[part 1 of 2: packages /VehicleProject to /Cluster]
AUTOSAR XML (schema 00048)
package /VehicleProject
  system System
package /TP
  can tp config KAMA_FP_EPT_0303_CAN: communication-cluster=KAMA_FP_EPT_0303, can-tp-ecu{cycle-time-main-function=0.005, ecu-instance=VCU}
    can tp channel TPCH: channel-id=1, channel-mode=FULL-DUPLEX-MODE
    can-tp-connection addressing-format=STANDARD, can-tp-channel=TPCH, data-pdu=AllFunctionRequest_Tp_oKAMA_FP_EPT_0303, receiver=TN_VCU, ta-type=FUNCTIONAL, tp-sdu=AllFunctionRequest_oKAMA_FP_EPT_0303, transmitter=TN_Diag:
      ident AllFunctionRequest_oTN_Diag
    can-tp-connection addressing-format=STANDARD, can-tp-channel=TPCH, data-pdu=OBDFunRequest_Tp_oKAMA_FP_EPT_0303, receiver=TN_VCU, ta-type=FUNCTIONAL, tp-sdu=OBDFunRequest_oKAMA_FP_EPT_0303, transmitter=TN_OBDDiag:
      ident OBDFunRequest_oTN_OBDDiag
    can-tp-connection addressing-format=STANDARD, can-tp-channel=TPCH, data-pdu=UDSFunRequest_Tp_oKAMA_FP_EPT_0303, receiver=TN_VCU, ta-type=FUNCTIONAL, tp-sdu=UDSFunRequest_oKAMA_FP_EPT_0303, transmitter=TN_Diag:
      ident UDSFunRequest_oTN_Diag
    can-tp-connection addressing-format=STANDARD, can-tp-channel=TPCH, data-pdu=OBDRequest_Tp_oKAMA_FP_EPT_0303, flow-control-pdu=OBDResponse_Tp_oKAMA_FP_EPT_0303, receiver=TN_VCU, ta-type=PHYSICAL, tp-sdu=OBDRequest_oKAMA_FP_EPT_0303, transmitter=TN_OBDDiag:
      ident OBDRequest_oTN_VCU
    can-tp-connection addressing-format=STANDARD, can-tp-channel=TPCH, data-pdu=OBDResponse_Tp_oKAMA_FP_EPT_0303, flow-control-pdu=OBDRequest_Tp_oKAMA_FP_EPT_0303, receiver=TN_OBDDiag, ta-type=PHYSICAL, tp-sdu=OBDResponse_oKAMA_FP_EPT_0303, transmitter=TN_VCU:
      ident OBDResponse_oTN_VCU
    can-tp-connection addressing-format=STANDARD, can-tp-channel=TPCH, data-pdu=UDSRequest_Tp_oKAMA_FP_EPT_0303, flow-control-pdu=UDSResponse_Tp_oKAMA_FP_EPT_0303, receiver=TN_VCU, ta-type=PHYSICAL, tp-sdu=UDSRequest_oKAMA_FP_EPT_0303, transmitter=TN_Diag:
      ident UDSRequest_oTN_VCU
    can-tp-connection addressing-format=STANDARD, can-tp-channel=TPCH, data-pdu=UDSResponse_Tp_oKAMA_FP_EPT_0303, flow-control-pdu=UDSRequest_Tp_oKAMA_FP_EPT_0303, receiver=TN_Diag, ta-type=PHYSICAL, tp-sdu=UDSResponse_oKAMA_FP_EPT_0303, transmitter=TN_VCU:
      ident UDSResponse_oTN_VCU
    can tp node TN_Diag
    can tp node TN_OBDDiag
    can tp node TN_VCU: connector=CN_KAMA_FP_EPT_0303
package /Cluster
  can cluster KAMA_FP_EPSChassis1_0303: baudrate=500000, protocol-name=CAN
    can physical channel CHNL: comm-connectors=CN_KAMA_FP_EPSChassis1_0303
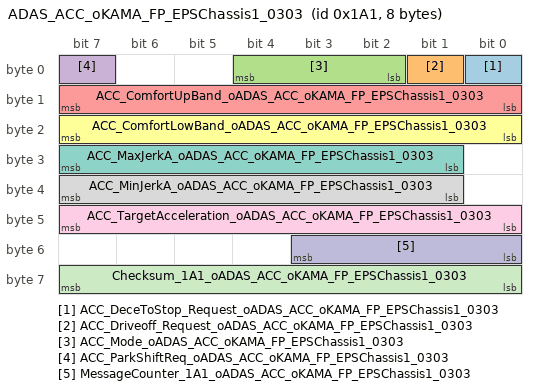
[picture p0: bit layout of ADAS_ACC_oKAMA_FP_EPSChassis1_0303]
      frame ADAS_ACC_oKAMA_FP_EPSChassis1_0303: id 0x1A1, to VCU, frame-length=8, can-addressing-mode=STANDARD
        pdu ADAS_ACC_oKAMA_FP_EPSChassis1_0303: length=8, minimum-delay=0, transmission-mode-false-timing=cyclic-timing={time-offset=0, time-period=0.02}, transmission-mode-true-timing=cyclic-timing={time-offset=0, time-period=0.02}, unused-bit-pattern=0
          signal ACC_DeceToStop_Request_oADAS_ACC_oKAMA_FP_EPSChassis1_0303: start 0, 1 bit, big-endian, i-signal-type=PRIMITIVE, init-value=0, base-type=boolean, compu-method=CM_ACC_DeceToStop_Request, data-constr=DC_ACC_DeceToStop_Request, transfer-property=PENDING, to VCU
          signal ACC_Driveoff_Request_oADAS_ACC_oKAMA_FP_EPSChassis1_0303: start 1, 1 bit, big-endian, i-signal-type=PRIMITIVE, init-value=0, base-type=boolean, compu-method=CM_ACC_Driveoff_Request, data-constr=DC_ACC_Driveoff_Request, transfer-property=PENDING, to VCU
          signal ACC_Mode_oADAS_ACC_oKAMA_FP_EPSChassis1_0303: start 4, 3 bit, big-endian, i-signal-type=PRIMITIVE, init-value=0, base-type=uint8, compu-method=CM_ACC_Mode, data-constr=DC_ACC_Mode, transfer-property=PENDING, to VCU
          signal ACC_ParkShiftReq_oADAS_ACC_oKAMA_FP_EPSChassis1_0303: start 7, 1 bit, big-endian, i-signal-type=PRIMITIVE, init-value=0, base-type=boolean, compu-method=CM_ACC_ParkShiftReq, data-constr=DC_ACC_ParkShiftReq, transfer-property=PENDING, to VCU
          signal ACC_ComfortUpBand_oADAS_ACC_oKAMA_FP_EPSChassis1_0303: start 15, 8 bit, big-endian, i-signal-type=PRIMITIVE, init-value=140, base-type=uint8, compu-method=CM_ACC_ComfortUpBand, data-constr=DC_ACC_ComfortUpBand, transfer-property=PENDING, to VCU
          signal ACC_ComfortLowBand_oADAS_ACC_oKAMA_FP_EPSChassis1_0303: start 23, 8 bit, big-endian, i-signal-type=PRIMITIVE, init-value=140, base-type=uint8, compu-method=CM_ACC_ComfortLowBand, data-constr=DC_ACC_ComfortLowBand, transfer-property=PENDING, to VCU
          signal ACC_MaxJerkA_oADAS_ACC_oKAMA_FP_EPSChassis1_0303: start 31, 7 bit, big-endian, i-signal-type=PRIMITIVE, init-value=0, base-type=uint8, compu-method=CM_ACC_MaxJerkA, data-constr=DC_ACC_MaxJerkA, transfer-property=PENDING, to VCU
          signal ACC_MinJerkA_oADAS_ACC_oKAMA_FP_EPSChassis1_0303: start 39, 7 bit, big-endian, i-signal-type=PRIMITIVE, init-value=127, base-type=uint8, compu-method=CM_ACC_MinJerkA, data-constr=DC_ACC_MinJerkA, transfer-property=PENDING, to VCU
          signal ACC_TargetAcceleration_oADAS_ACC_oKAMA_FP_EPSChassis1_0303: start 47, 8 bit, big-endian, i-signal-type=PRIMITIVE, init-value=140, base-type=uint8, compu-method=CM_ACC_TargetAcceleration, data-constr=DC_ACC_TargetAcceleration, unit=U_mYsX2, transfer-property=PENDING, to VCU
          signal MessageCounter_1A1_oADAS_ACC_oKAMA_FP_EPSChassis1_0303: start 51, 4 bit, big-endian, i-signal-type=PRIMITIVE, init-value=0, base-type=uint8, compu-method=CM_MessageCounter_1A1, data-constr=DC_MessageCounter_1A1, transfer-property=PENDING, to VCU
          signal Checksum_1A1_oADAS_ACC_oKAMA_FP_EPSChassis1_0303: start 63, 8 bit, big-endian, i-signal-type=PRIMITIVE, init-value=0, base-type=uint8, compu-method=CM_Checksum_1A1, data-constr=DC_Checksum_1A1, transfer-property=PENDING, to VCU
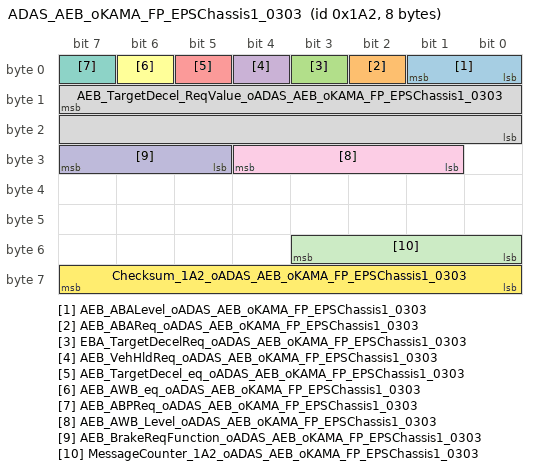
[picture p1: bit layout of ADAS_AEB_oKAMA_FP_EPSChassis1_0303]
      frame ADAS_AEB_oKAMA_FP_EPSChassis1_0303: id 0x1A2, to VCU, frame-length=8, can-addressing-mode=STANDARD
        pdu ADAS_AEB_oKAMA_FP_EPSChassis1_0303: length=8, minimum-delay=0, transmission-mode-false-timing=cyclic-timing={time-offset=0, time-period=0.02}, transmission-mode-true-timing=cyclic-timing={time-offset=0, time-period=0.02}, unused-bit-pattern=0
          signal AEB_ABALevel_oADAS_AEB_oKAMA_FP_EPSChassis1_0303: start 1, 2 bit, big-endian, i-signal-type=PRIMITIVE, init-value=0, base-type=uint8, compu-method=CM_AEB_ABALevel, data-constr=DC_AEB_ABALevel, transfer-property=PENDING, to VCU
          signal AEB_ABAReq_oADAS_AEB_oKAMA_FP_EPSChassis1_0303: start 2, 1 bit, big-endian, i-signal-type=PRIMITIVE, init-value=0, base-type=boolean, compu-method=CM_AEB_ABAReq, data-constr=DC_AEB_ABAReq, transfer-property=PENDING, to VCU
          signal EBA_TargetDecelReq_oADAS_AEB_oKAMA_FP_EPSChassis1_0303: start 3, 1 bit, big-endian, i-signal-type=PRIMITIVE, init-value=0, base-type=boolean, compu-method=CM_EBA_TargetDecelReq, data-constr=DC_EBA_TargetDecelReq, transfer-property=PENDING, to VCU
          signal AEB_VehHldReq_oADAS_AEB_oKAMA_FP_EPSChassis1_0303: start 4, 1 bit, big-endian, i-signal-type=PRIMITIVE, init-value=0, base-type=boolean, compu-method=CM_AEB_VehHldReq, data-constr=DC_AEB_VehHldReq, transfer-property=PENDING, to VCU
          signal AEB_TargetDecel_eq_oADAS_AEB_oKAMA_FP_EPSChassis1_0303: start 5, 1 bit, big-endian, i-signal-type=PRIMITIVE, init-value=0, base-type=boolean, compu-method=CM_AEB_TargetDecel_eq, data-constr=DC_AEB_TargetDecel_eq, transfer-property=PENDING, to VCU
          signal AEB_AWB_eq_oADAS_AEB_oKAMA_FP_EPSChassis1_0303: start 6, 1 bit, big-endian, i-signal-type=PRIMITIVE, init-value=0, base-type=boolean, compu-method=CM_AEB_AWB_eq, data-constr=DC_AEB_AWB_eq, transfer-property=PENDING, to VCU
          signal AEB_ABPReq_oADAS_AEB_oKAMA_FP_EPSChassis1_0303: start 7, 1 bit, big-endian, i-signal-type=PRIMITIVE, init-value=0, base-type=boolean, compu-method=CM_AEB_ABPReq, data-constr=DC_AEB_ABPReq, transfer-property=PENDING, to VCU
          signal AEB_TargetDecel_ReqValue_oADAS_AEB_oKAMA_FP_EPSChassis1_0303: start 15, 16 bit, big-endian, i-signal-type=PRIMITIVE, init-value=0, base-type=uint16, compu-method=CM_AEB_TargetDecel_ReqValue, data-constr=DC_AEB_TargetDecel_ReqValue, unit=U_mYs2, transfer-property=PENDING, to VCU
          signal AEB_AWB_Level_oADAS_AEB_oKAMA_FP_EPSChassis1_0303: start 28, 4 bit, big-endian, i-signal-type=PRIMITIVE, init-value=0, base-type=uint8, compu-method=CM_AEB_AWB_Level, data-constr=DC_AEB_AWB_Level, transfer-property=PENDING, to VCU
          signal AEB_BrakeReqFunction_oADAS_AEB_oKAMA_FP_EPSChassis1_0303: start 31, 3 bit, big-endian, i-signal-type=PRIMITIVE, init-value=0, base-type=uint8, compu-method=CM_AEB_BrakeReqFunction, data-constr=DC_AEB_BrakeReqFunction, transfer-property=PENDING, to VCU
          signal MessageCounter_1A2_oADAS_AEB_oKAMA_FP_EPSChassis1_0303: start 51, 4 bit, big-endian, i-signal-type=PRIMITIVE, init-value=0, base-type=uint8, compu-method=CM_MessageCounter_1A2, data-constr=DC_MessageCounter_1A2, transfer-property=PENDING, to VCU
          signal Checksum_1A2_oADAS_AEB_oKAMA_FP_EPSChassis1_0303: start 63, 8 bit, big-endian, i-signal-type=PRIMITIVE, init-value=0, base-type=uint8, compu-method=CM_Checksum_1A2, data-constr=DC_Checksum_1A2, transfer-property=PENDING, to VCU
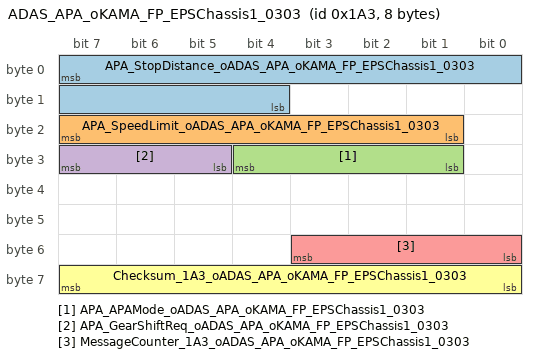
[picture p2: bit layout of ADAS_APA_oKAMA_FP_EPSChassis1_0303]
      frame ADAS_APA_oKAMA_FP_EPSChassis1_0303: id 0x1A3, to VCU, frame-length=8, can-addressing-mode=STANDARD
        pdu ADAS_APA_oKAMA_FP_EPSChassis1_0303: length=8, minimum-delay=0, transmission-mode-false-timing=cyclic-timing={time-offset=0, time-period=0.02}, transmission-mode-true-timing=cyclic-timing={time-offset=0, time-period=0.02}, unused-bit-pattern=0
          signal APA_StopDistance_oADAS_APA_oKAMA_FP_EPSChassis1_0303: start 7, 12 bit, big-endian, i-signal-type=PRIMITIVE, init-value=0, base-type=uint16, compu-method=CM_APA_StopDistance, data-constr=DC_APA_StopDistance, unit=U_cm, transfer-property=PENDING, to VCU
          signal APA_SpeedLimit_oADAS_APA_oKAMA_FP_EPSChassis1_0303: start 23, 7 bit, big-endian, i-signal-type=PRIMITIVE, init-value=0, base-type=uint8, compu-method=CM_APA_SpeedLimit, data-constr=DC_APA_SpeedLimit, unit=U_kph, transfer-property=PENDING, to VCU
          signal APA_APAMode_oADAS_APA_oKAMA_FP_EPSChassis1_0303: start 28, 4 bit, big-endian, i-signal-type=PRIMITIVE, init-value=0, base-type=uint8, compu-method=CM_APA_APAMode, data-constr=DC_APA_APAMode, transfer-property=PENDING, to VCU
          signal APA_GearShiftReq_oADAS_APA_oKAMA_FP_EPSChassis1_0303: start 31, 3 bit, big-endian, i-signal-type=PRIMITIVE, init-value=0, base-type=uint8, compu-method=CM_APA_GearShiftReq, data-constr=DC_APA_GearShiftReq, transfer-property=PENDING, to VCU
          signal MessageCounter_1A3_oADAS_APA_oKAMA_FP_EPSChassis1_0303: start 51, 4 bit, big-endian, i-signal-type=PRIMITIVE, init-value=0, base-type=uint8, compu-method=CM_MessageCounter_1A3, data-constr=DC_MessageCounter_1A3, transfer-property=PENDING, to VCU
          signal Checksum_1A3_oADAS_APA_oKAMA_FP_EPSChassis1_0303: start 63, 8 bit, big-endian, i-signal-type=PRIMITIVE, init-value=0, base-type=uint8, compu-method=CM_Checksum_1A3, data-constr=DC_Checksum_1A3, transfer-property=PENDING, to VCU
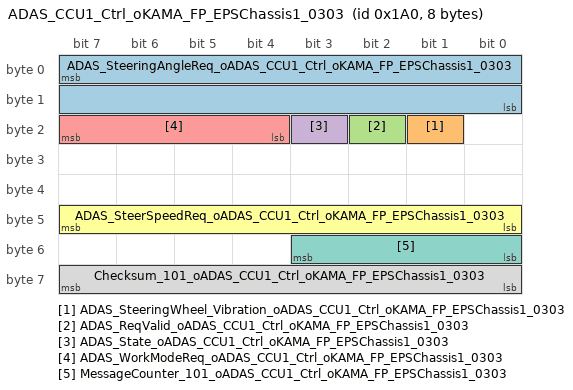
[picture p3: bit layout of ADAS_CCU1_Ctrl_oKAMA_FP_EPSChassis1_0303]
      frame ADAS_CCU1_Ctrl_oKAMA_FP_EPSChassis1_0303: id 0x1A0, to VCU, frame-length=8, can-addressing-mode=STANDARD
        pdu ADAS_CCU1_Ctrl_oKAMA_FP_EPSChassis1_0303: length=8, minimum-delay=0, transmission-mode-false-timing=cyclic-timing={time-offset=0, time-period=0.02}, transmission-mode-true-timing=cyclic-timing={time-offset=0, time-period=0.02}, unused-bit-pattern=0
          signal ADAS_SteeringAngleReq_oADAS_CCU1_Ctrl_oKAMA_FP_EPSChassis1_0303: start 7, 16 bit, big-endian, i-signal-type=PRIMITIVE, init-value=7380, base-type=uint16, compu-method=CM_ADAS_SteeringAngleReq, data-constr=DC_ADAS_SteeringAngleReq, unit=U_deg, transfer-property=PENDING, to VCU  # ADAS request Steering wheel steering target angle ·½ÏòÅÌ×ªÏòÄ¿±ê½Ç¶È
          signal ADAS_SteeringWheel_Vibration_oADAS_CCU1_Ctrl_oKAMA_FP_EPSChassis1_0303: start 17, 1 bit, big-endian, i-signal-type=PRIMITIVE, init-value=0, base-type=boolean, compu-method=CM_ADAS_SteeringWheel_Vibration, data-constr=DC_ADAS_SteeringWheel_Vibration, transfer-property=PENDING, to VCU
          signal ADAS_ReqValid_oADAS_CCU1_Ctrl_oKAMA_FP_EPSChassis1_0303: start 18, 1 bit, big-endian, i-signal-type=PRIMITIVE, init-value=0, base-type=boolean, compu-method=CM_ADAS_ReqValid, data-constr=DC_ADAS_ReqValid, transfer-property=PENDING, to VCU  # ADAS angle request valid status ×ª½ÇÖ¸ÁîÓÐÐ§Î»
          signal ADAS_State_oADAS_CCU1_Ctrl_oKAMA_FP_EPSChassis1_0303: start 19, 1 bit, big-endian, i-signal-type=PRIMITIVE, init-value=0, base-type=boolean, compu-method=CM_ADAS_State, data-constr=DC_ADAS_State, transfer-property=PENDING, to VCU  # ADAS valid status ×´Ì¬ÓÐÐ§Î»
          signal ADAS_WorkModeReq_oADAS_CCU1_Ctrl_oKAMA_FP_EPSChassis1_0303: start 23, 4 bit, big-endian, i-signal-type=PRIMITIVE, init-value=0, base-type=uint8, compu-method=CM_ADAS_WorkModeReq, data-constr=DC_ADAS_WorkModeReq, transfer-property=PENDING, to VCU  # ADAS request steering work mode ¿ØÖÆÆ÷¹¤×÷Ä£Ê½Ö¸Áî
          signal ADAS_SteerSpeedReq_oADAS_CCU1_Ctrl_oKAMA_FP_EPSChassis1_0303: start 47, 8 bit, big-endian, i-signal-type=PRIMITIVE, init-value=0, base-type=uint8, compu-method=CM_ADAS_SteerSpeedReq, data-constr=DC_ADAS_SteerSpeedReq, unit=U_degYs, transfer-property=PENDING, to VCU  # ADAS request Steering wheel steering target angular speed ·½ÏòÅÌ×ªÏòÄ¿±ê½ÇËÙ¶È
          signal MessageCounter_101_oADAS_CCU1_Ctrl_oKAMA_FP_EPSChassis1_0303: start 51, 4 bit, big-endian, i-signal-type=PRIMITIVE, init-value=0, base-type=uint8, compu-method=CM_MessageCounter_101, data-constr=DC_MessageCounter_101, transfer-property=PENDING, to VCU  # Alive Counter ´Ó0µ½15Ñ­»·¼ÆÊý
          signal Checksum_101_oADAS_CCU1_Ctrl_oKAMA_FP_EPSChassis1_0303: start 63, 8 bit, big-endian, i-signal-type=PRIMITIVE, init-value=0, base-type=uint8, compu-method=CM_Checksum_101, data-constr=DC_Checksum_101, transfer-property=PENDING, to VCU
      frame DonorCar_ACM_Status_oKAMA_FP_EPSChassis1_0303: id 0x380, to VCU, frame-length=8, can-addressing-mode=STANDARD
        pdu DonorCar_ACM_Status_oKAMA_FP_EPSChassis1_0303: length=8, minimum-delay=0, transmission-mode-false-timing=cyclic-timing={time-offset=0, time-period=0.02}, transmission-mode-true-timing=cyclic-timing={time-offset=0, time-period=0.02}, unused-bit-pattern=0
          signal ACU_DrvSeatbeltBucklestatus_oDonorCar_ACM_Status_oKAMA_FP_EPSChassis1_0303: start 0, 1 bit, big-endian, i-signal-type=PRIMITIVE, init-value=0, base-type=boolean, compu-method=CM_ACU_DrvSeatbeltBucklestatus, data-constr=DC_ACU_DrvSeatbeltBucklestatus, transfer-property=PENDING, to VCU
          signal ACU_PassSeatbeltBucklestatus_oDonorCar_ACM_Status_oKAMA_FP_EPSChassis1_0303: start 1, 1 bit, big-endian, i-signal-type=PRIMITIVE, init-value=0, base-type=boolean, compu-method=CM_ACU_PassSeatbeltBucklestatus, data-constr=DC_ACU_PassSeatbeltBucklestatus, transfer-property=PENDING, to VCU
      frame DonorCar_BCM_LDoorWindowState_oKAMA_FP_EPSChassis1_0303: id 0x285, to VCU, frame-length=8, can-addressing-mode=STANDARD
        pdu DonorCar_BCM_LDoorWindowState_oKAMA_FP_EPSChassis1_0303: length=8, minimum-delay=0, transmission-mode-false-timing=cyclic-timing={time-offset=0, time-period=0.1}, transmission-mode-true-timing=cyclic-timing={time-offset=0, time-period=0.1}, unused-bit-pattern=0
          signal BCM_FrontLeftDoorAjarStatus_oDonorCar_BCM_LDoorWindowState_oKAMA_FP_EPSChassis1_0303: start 32, 1 bit, big-endian, i-signal-type=PRIMITIVE, init-value=0, base-type=boolean, compu-method=CM_BCM_FrontLeftDoorAjarStatus, data-constr=DC_BCM_FrontLeftDoorAjarStatus, transfer-property=PENDING, to VCU
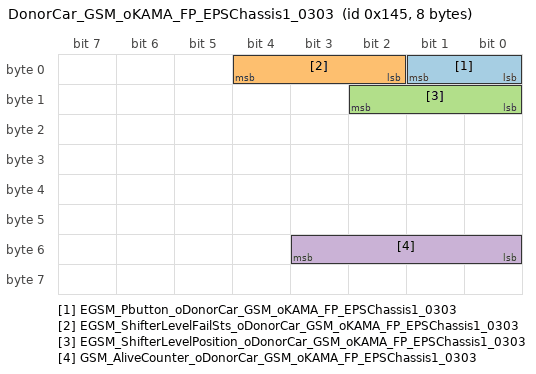
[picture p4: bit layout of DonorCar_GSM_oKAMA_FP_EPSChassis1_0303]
      frame DonorCar_GSM_oKAMA_FP_EPSChassis1_0303: id 0x145, to VCU, frame-length=8, can-addressing-mode=STANDARD
        pdu DonorCar_GSM_oKAMA_FP_EPSChassis1_0303: length=8, minimum-delay=0, transmission-mode-false-timing=cyclic-timing={time-offset=0, time-period=0.02}, transmission-mode-true-timing=cyclic-timing={time-offset=0, time-period=0.02}, unused-bit-pattern=0
          signal EGSM_Pbutton_oDonorCar_GSM_oKAMA_FP_EPSChassis1_0303: start 1, 2 bit, big-endian, i-signal-type=PRIMITIVE, init-value=0, base-type=uint8, compu-method=CM_EGSM_Pbutton, data-constr=DC_EGSM_Pbutton, transfer-property=PENDING, to VCU
          signal EGSM_ShifterLevelFailSts_oDonorCar_GSM_oKAMA_FP_EPSChassis1_0303: start 4, 3 bit, big-endian, i-signal-type=PRIMITIVE, init-value=0, base-type=uint8, compu-method=CM_EGSM_ShifterLevelFailSts, data-constr=DC_EGSM_ShifterLevelFailSts, transfer-property=PENDING, to VCU
          signal EGSM_ShifterLevelPosition_oDonorCar_GSM_oKAMA_FP_EPSChassis1_0303: start 10, 3 bit, big-endian, i-signal-type=PRIMITIVE, init-value=0, base-type=uint8, compu-method=CM_EGSM_ShifterLevelPosition, data-constr=DC_EGSM_ShifterLevelPosition, transfer-property=PENDING, to VCU
          signal GSM_AliveCounter_oDonorCar_GSM_oKAMA_FP_EPSChassis1_0303: start 51, 4 bit, big-endian, i-signal-type=PRIMITIVE, init-value=0, base-type=uint8, compu-method=CM_GSM_AliveCounter, data-constr=DC_GSM_AliveCounter, transfer-property=PENDING, to VCU  # message alive counter
      frame DonorCar_MMI_Status_Infor_oKAMA_FP_EPSChassis1_0303: id 0x2A4, to VCU, frame-length=8, can-addressing-mode=STANDARD
        pdu DonorCar_MMI_Status_Infor_oKAMA_FP_EPSChassis1_0303: length=8, minimum-delay=0, transmission-mode-false-timing=cyclic-timing={time-offset=0, time-period=0.1}, transmission-mode-true-timing=cyclic-timing={time-offset=0, time-period=0.1}, unused-bit-pattern=0
          signal MMI_DriverModeReq_oDonorCar_MMI_Status_Infor_oKAMA_FP_EPSChassis1_0303: start 42, 3 bit, big-endian, i-signal-type=PRIMITIVE, init-value=0, base-type=uint8, compu-method=CM_MMI_DriverModeReq, data-constr=DC_MMI_DriverModeReq, transfer-property=PENDING, to VCU
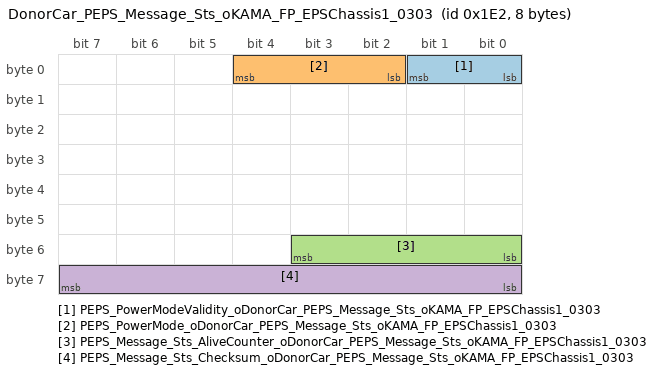
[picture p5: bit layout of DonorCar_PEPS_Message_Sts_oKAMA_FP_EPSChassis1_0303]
      frame DonorCar_PEPS_Message_Sts_oKAMA_FP_EPSChassis1_0303: id 0x1E2, to VCU, frame-length=8, can-addressing-mode=STANDARD
        pdu DonorCar_PEPS_Message_Sts_oKAMA_FP_EPSChassis1_0303: length=8, minimum-delay=0, transmission-mode-false-timing=cyclic-timing={time-offset=0, time-period=0.02}, transmission-mode-true-timing=cyclic-timing={time-offset=0, time-period=0.02}, unused-bit-pattern=0
          signal PEPS_PowerModeValidity_oDonorCar_PEPS_Message_Sts_oKAMA_FP_EPSChassis1_0303: start 1, 2 bit, big-endian, i-signal-type=PRIMITIVE, init-value=0, base-type=uint8, compu-method=CM_PEPS_PowerModeValidity, data-constr=DC_PEPS_PowerModeValidity, transfer-property=PENDING, to VCU  # PEPS Power Distribution StatusValidity bit
          signal PEPS_PowerMode_oDonorCar_PEPS_Message_Sts_oKAMA_FP_EPSChassis1_0303: start 4, 3 bit, big-endian, i-signal-type=PRIMITIVE, init-value=0, base-type=uint8, compu-method=CM_PEPS_PowerMode, data-constr=DC_PEPS_PowerMode, transfer-property=PENDING, to VCU  # PEPS Power Distribution Status
          signal PEPS_Message_Sts_AliveCounter_oDonorCar_PEPS_Message_Sts_oKAMA_FP_EPSChassis1_0303: start 51, 4 bit, big-endian, i-signal-type=PRIMITIVE, init-value=0, base-type=uint8, compu-method=CM_PEPS_Message_Sts_AliveCounter, data-constr=DC_PEPS_Message_Sts_AliveCounter, transfer-property=PENDING, to VCU  # message alive counter
          signal PEPS_Message_Sts_Checksum_oDonorCar_PEPS_Message_Sts_oKAMA_FP_EPSChassis1_0303: start 63, 8 bit, big-endian, i-signal-type=PRIMITIVE, init-value=0, base-type=uint8, compu-method=CM_PEPS_Message_Sts_Checksum, data-constr=DC_PEPS_Message_Sts_Checksum, transfer-property=PENDING, to VCU  # message checksum
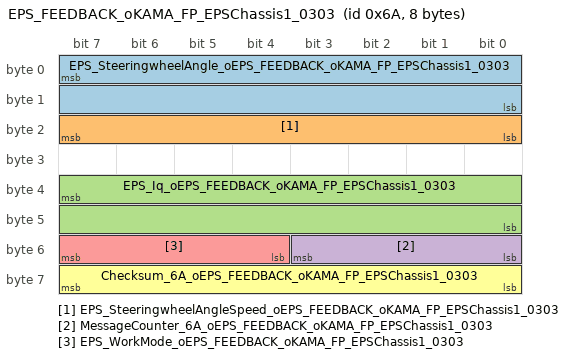
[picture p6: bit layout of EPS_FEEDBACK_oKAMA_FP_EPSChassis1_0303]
      frame EPS_FEEDBACK_oKAMA_FP_EPSChassis1_0303: id 0x6A, to VCU, frame-length=8, can-addressing-mode=STANDARD
        pdu EPS_FEEDBACK_oKAMA_FP_EPSChassis1_0303: length=8, minimum-delay=0, transmission-mode-false-timing=cyclic-timing={time-offset=0, time-period=0.02}, transmission-mode-true-timing=cyclic-timing={time-offset=0, time-period=0.02}, unused-bit-pattern=0
          signal EPS_SteeringwheelAngle_oEPS_FEEDBACK_oKAMA_FP_EPSChassis1_0303: start 7, 16 bit, big-endian, i-signal-type=PRIMITIVE, init-value=7380, base-type=uint16, compu-method=CM_EPS_SteeringwheelAngle, data-constr=DC_EPS_SteeringwheelAngle, unit=U_deg, transfer-property=PENDING, to VCU  # Steering wheel angle ·½ÏòÅÌ×ªÏò½Ç¶È
          signal EPS_SteeringwheelAngleSpeed_oEPS_FEEDBACK_oKAMA_FP_EPSChassis1_0303: start 23, 8 bit, big-endian, i-signal-type=PRIMITIVE, init-value=0, base-type=uint8, compu-method=CM_EPS_SteeringwheelAngleSpeed, data-constr=DC_EPS_SteeringwheelAngleSpeed, unit=U_degYs, transfer-property=PENDING, to VCU  # Steering wheel angle Speed ·½ÏòÅÌ×ªÏò½ÇËÙ¶È
          signal EPS_Iq_oEPS_FEEDBACK_oKAMA_FP_EPSChassis1_0303: start 39, 16 bit, big-endian, i-signal-type=PRIMITIVE, init-value=10000, base-type=uint16, compu-method=CM_EPS_Iq, data-constr=DC_EPS_Iq, transfer-property=PENDING, to VCU  # Steering Iq current ×ªÏòqÖá·´À¡µçÁ÷
          signal MessageCounter_6A_oEPS_FEEDBACK_oKAMA_FP_EPSChassis1_0303: start 51, 4 bit, big-endian, i-signal-type=PRIMITIVE, init-value=0, base-type=uint8, compu-method=CM_MessageCounter_6A, data-constr=DC_MessageCounter_6A, transfer-property=PENDING, to VCU  # Alive Counter ´Ó0µ½15Ñ­»·¼ÆÊý
          signal EPS_WorkMode_oEPS_FEEDBACK_oKAMA_FP_EPSChassis1_0303: start 55, 4 bit, big-endian, i-signal-type=PRIMITIVE, init-value=0, base-type=uint8, compu-method=CM_EPS_WorkMode, data-constr=DC_EPS_WorkMode, transfer-property=PENDING, to VCU  # EPS Working mode EPS¹¤×÷Ä£Ê½
          signal Checksum_6A_oEPS_FEEDBACK_oKAMA_FP_EPSChassis1_0303: start 63, 8 bit, big-endian, i-signal-type=PRIMITIVE, init-value=0, base-type=uint8, compu-method=CM_Checksum_6A, data-constr=DC_Checksum_6A, transfer-property=PENDING, to VCU
      frame GW_TCU_AmbientTemp_oKAMA_FP_EPSChassis1_0303: id 0x2C2, to VCU, frame-length=8, can-addressing-mode=STANDARD
        pdu GW_TCU_AmbientTemp_oKAMA_FP_EPSChassis1_0303: length=8, minimum-delay=0, transmission-mode-false-timing=cyclic-timing={time-offset=0, time-period=1}, transmission-mode-true-timing=cyclic-timing={time-offset=0, time-period=1}, unused-bit-pattern=0
          signal TCU_ambientTemperature_oGW_TCU_AmbientTemp_oKAMA_FP_EPSChassis1_0303: start 7, 8 bit, big-endian, i-signal-type=PRIMITIVE, init-value=50, base-type=uint8, compu-method=CM_TCU_ambientTemperature, data-constr=DC_TCU_ambientTemperature, transfer-property=PENDING, to VCU
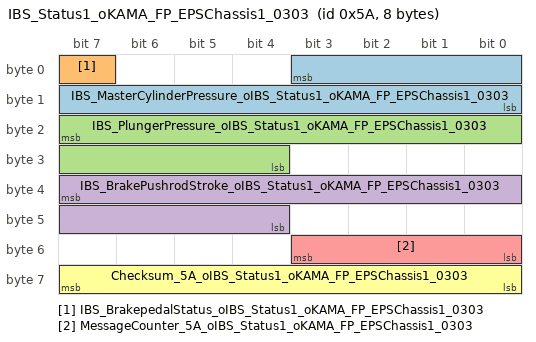
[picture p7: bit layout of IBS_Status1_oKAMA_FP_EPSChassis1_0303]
      frame IBS_Status1_oKAMA_FP_EPSChassis1_0303: id 0x5A, to VCU, frame-length=8, can-addressing-mode=STANDARD
        pdu IBS_Status1_oKAMA_FP_EPSChassis1_0303: length=8, minimum-delay=0, transmission-mode-false-timing=cyclic-timing={time-offset=0, time-period=0.02}, transmission-mode-true-timing=cyclic-timing={time-offset=0, time-period=0.02}, unused-bit-pattern=0
          signal IBS_MasterCylinderPressure_oIBS_Status1_oKAMA_FP_EPSChassis1_0303: start 3, 12 bit, big-endian, i-signal-type=PRIMITIVE, init-value=0, base-type=uint16, compu-method=CM_IBS_MasterCylinderPressure, data-constr=DC_IBS_MasterCylinderPressure, unit=U_BAR, transfer-property=PENDING, to VCU  # EN:Master Cylinder Pressure signal CH£ºÖ÷¸×Ñ¹Á¦ÊýÖµ
          signal IBS_BrakepedalStatus_oIBS_Status1_oKAMA_FP_EPSChassis1_0303: start 7, 1 bit, big-endian, i-signal-type=PRIMITIVE, init-value=0, base-type=boolean, compu-method=CM_IBS_BrakepedalStatus, data-constr=DC_IBS_BrakepedalStatus, transfer-property=PENDING, to VCU
          signal IBS_PlungerPressure_oIBS_Status1_oKAMA_FP_EPSChassis1_0303: start 23, 12 bit, big-endian, i-signal-type=PRIMITIVE, init-value=0, base-type=uint16, compu-method=CM_IBS_PlungerPressure, data-constr=DC_IBS_PlungerPressure, unit=U_BAR, transfer-property=PENDING, to VCU  # pressure of PSU
          signal IBS_BrakePushrodStroke_oIBS_Status1_oKAMA_FP_EPSChassis1_0303: start 39, 12 bit, big-endian, i-signal-type=PRIMITIVE, init-value=320, base-type=uint16, compu-method=CM_IBS_BrakePushrodStroke, data-constr=DC_IBS_BrakePushrodStroke, unit=U_mm, transfer-property=PENDING, to VCU  # IBS pushrod stroke
          signal MessageCounter_5A_oIBS_Status1_oKAMA_FP_EPSChassis1_0303: start 51, 4 bit, big-endian, i-signal-type=PRIMITIVE, init-value=0, base-type=uint8, compu-method=CM_MessageCounter_5A, data-constr=DC_MessageCounter_5A, transfer-property=PENDING, to VCU
          signal Checksum_5A_oIBS_Status1_oKAMA_FP_EPSChassis1_0303: start 63, 8 bit, big-endian, i-signal-type=PRIMITIVE, init-value=0, base-type=uint8, compu-method=CM_Checksum_5A, data-constr=DC_Checksum_5A, transfer-property=PENDING, to VCU
      frame IBS_Status2_oKAMA_FP_EPSChassis1_0303: id 0x5B, to VCU, frame-length=8, can-addressing-mode=STANDARD
        pdu IBS_Status2_oKAMA_FP_EPSChassis1_0303: length=8, minimum-delay=0, transmission-mode-false-timing=cyclic-timing={time-offset=0, time-period=0.02}, transmission-mode-true-timing=cyclic-timing={time-offset=0, time-period=0.02}, unused-bit-pattern=0
          signal IBS_EPBTxtdisplay_oIBS_Status2_oKAMA_FP_EPSChassis1_0303: start 3, 4 bit, big-endian, i-signal-type=PRIMITIVE, init-value=0, base-type=uint8, compu-method=CM_IBS_EPBTxtdisplay, data-constr=DC_IBS_EPBTxtdisplay, transfer-property=PENDING, to VCU  # EN: EPB Text display CH: EPBÎÄ×ÖÌáÊ¾
          signal IBS_BrakeLightRequest_oIBS_Status2_oKAMA_FP_EPSChassis1_0303: start 5, 2 bit, big-endian, i-signal-type=PRIMITIVE, init-value=0, base-type=uint8, compu-method=CM_IBS_BrakeLightRequest, data-constr=DC_IBS_BrakeLightRequest, transfer-property=PENDING, to VCU  # EN:ESC request to illuminate the brake lights when the function is triggered CH:´¥·¢Ö÷¶¯ÖÆ¶¯Ê±£¬ESCÇëÇóµãÁÁÖÆ¶¯Î²µÆ
          signal IBS_EPBFailureLamp_oIBS_Status2_oKAMA_FP_EPSChassis1_0303: start 7, 2 bit, big-endian, i-signal-type=PRIMITIVE, init-value=0, base-type=uint8, compu-method=CM_IBS_EPBFailureLamp, data-constr=DC_IBS_EPBFailureLamp, transfer-property=PENDING, to VCU  # EN: EPB Failure Lamp CH: ´íÎóÖ¸Ê¾µÆ
          signal EPB_failurestatus_oIBS_Status2_oKAMA_FP_EPSChassis1_0303: start 14, 1 bit, big-endian, i-signal-type=PRIMITIVE, init-value=0, base-type=boolean, compu-method=CM_EPB_failurestatus, data-constr=DC_EPB_failurestatus, transfer-property=PENDING, to VCU  # EPB failure status
          signal BBF_failurestatus_oIBS_Status2_oKAMA_FP_EPSChassis1_0303: start 15, 1 bit, big-endian, i-signal-type=PRIMITIVE, init-value=0, base-type=boolean, compu-method=CM_BBF_failurestatus, data-constr=DC_BBF_failurestatus, transfer-property=PENDING, to VCU  # BBF failure status
          signal IBS_EPBworkingStatus_oIBS_Status2_oKAMA_FP_EPSChassis1_0303: start 17, 2 bit, big-endian, i-signal-type=PRIMITIVE, init-value=0, base-type=uint8, compu-method=CM_IBS_EPBworkingStatus, data-constr=DC_IBS_EPBworkingStatus, transfer-property=PENDING, to VCU  # EN: EPB Status CH: EPB×´Ì¬
          signal IBS_HDCActive_oIBS_Status2_oKAMA_FP_EPSChassis1_0303: start 19, 2 bit, big-endian, i-signal-type=PRIMITIVE, init-value=0, base-type=uint8, compu-method=CM_IBS_HDCActive, data-constr=DC_IBS_HDCActive, transfer-property=PENDING, to VCU  # EN:HDC Function Active CH:HDC ¹¦ÄÜ¼¤»î±êÖ¾Î»
          signal IBS_TCSActive_oIBS_Status2_oKAMA_FP_EPSChassis1_0303: start 24, 1 bit, big-endian, i-signal-type=PRIMITIVE, init-value=0, base-type=boolean, compu-method=CM_IBS_TCSActive, data-constr=DC_IBS_TCSActive, transfer-property=PENDING, to VCU  # EN:Tindicates TCS intervention active£¬TCS will detect spinning wheels and request torque reduction/limitation CH:CS¼¤»î±êÖ¾Î»
          signal IBS_VDCActive_oIBS_Status2_oKAMA_FP_EPSChassis1_0303: start 25, 1 bit, big-endian, i-signal-type=PRIMITIVE, init-value=0, base-type=boolean, compu-method=CM_IBS_VDCActive, data-constr=DC_IBS_VDCActive, transfer-property=PENDING, to VCU  # EN:indicates VDC intervention active£¬ ESP will detect other vehicle slip/slide situations, and brake individual wheels to counteract the vehicle slid
          signal IBS_CDPActive_oIBS_Status2_oKAMA_FP_EPSChassis1_0303: start 26, 1 bit, big-endian, i-signal-type=PRIMITIVE, init-value=0, base-type=boolean, compu-method=CM_IBS_CDPActive, data-constr=DC_IBS_CDPActive, transfer-property=PENDING, to VCU  # EN:CDP Function Active
          signal IBS_CDPAvailable_oIBS_Status2_oKAMA_FP_EPSChassis1_0303: start 27, 1 bit, big-endian, i-signal-type=PRIMITIVE, init-value=0, base-type=boolean, compu-method=CM_IBS_CDPAvailable, data-constr=DC_IBS_CDPAvailable, transfer-property=PENDING, to VCU  # EN:CDP Function Available CH:CDP ¹¦ÄÜ¿ÉÓÃ×´Ì¬
          signal IBS_HDCAvailable_oIBS_Status2_oKAMA_FP_EPSChassis1_0303: start 28, 1 bit, big-endian, i-signal-type=PRIMITIVE, init-value=0, base-type=boolean, compu-method=CM_IBS_HDCAvailable, data-constr=DC_IBS_HDCAvailable, transfer-property=PENDING, to VCU  # EN:HDC Function Available CH:HDC ¹¦ÄÜ¿ÉÓÃ×´Ì¬
          signal IBS_AEBActive_oIBS_Status2_oKAMA_FP_EPSChassis1_0303: start 29, 1 bit, big-endian, i-signal-type=PRIMITIVE, init-value=0, base-type=boolean, compu-method=CM_IBS_AEBActive, data-constr=DC_IBS_AEBActive, transfer-property=PENDING, to VCU  # EN:AEB Function Active CH:AEB ¹¦ÄÜ¼¤»î±êÖ¾Î»
          signal IBS_ECDActive_oIBS_Status2_oKAMA_FP_EPSChassis1_0303: start 30, 1 bit, big-endian, i-signal-type=PRIMITIVE, init-value=0, base-type=boolean, compu-method=CM_IBS_ECDActive, data-constr=DC_IBS_ECDActive, transfer-property=PENDING, to VCU  # EN:ECD Function Active CH:ECD ¹¦ÄÜ¼¤»î±êÖ¾Î»
          signal IBS_HHCActive_oIBS_Status2_oKAMA_FP_EPSChassis1_0303: start 31, 1 bit, big-endian, i-signal-type=PRIMITIVE, init-value=0, base-type=boolean, compu-method=CM_IBS_HHCActive, data-constr=DC_IBS_HHCActive, transfer-property=PENDING, to VCU  # EN:HHC Function Active CH:HHC ¹¦ÄÜ¼¤»î±êÖ¾Î»
          signal IBS_HHCAvailable_oIBS_Status2_oKAMA_FP_EPSChassis1_0303: start 32, 1 bit, big-endian, i-signal-type=PRIMITIVE, init-value=0, base-type=boolean, compu-method=CM_IBS_HHCAvailable, data-constr=DC_IBS_HHCAvailable, transfer-property=PENDING, to VCU  # EN:HHC Function Available CH:HHC ¹¦ÄÜ¿ÉÓÃ×´Ì¬
          signal IBS_AVHAvailable_oIBS_Status2_oKAMA_FP_EPSChassis1_0303: start 33, 1 bit, big-endian, i-signal-type=PRIMITIVE, init-value=0, base-type=boolean, compu-method=CM_IBS_AVHAvailable, data-constr=DC_IBS_AVHAvailable, transfer-property=PENDING, to VCU  # EN:AVH Function Available CH:AVH ¹¦ÄÜ¿ÉÓÃ×´Ì¬
          signal IBS_AVHActive_oIBS_Status2_oKAMA_FP_EPSChassis1_0303: start 34, 1 bit, big-endian, i-signal-type=PRIMITIVE, init-value=0, base-type=boolean, compu-method=CM_IBS_AVHActive, data-constr=DC_IBS_AVHActive, transfer-property=PENDING, to VCU  # EN:AVH Function Active CH:AVH ¹¦ÄÜ¼¤»î±êÖ¾Î»
          signal IBS_LiquidAlarm_oIBS_Status2_oKAMA_FP_EPSChassis1_0303: start 35, 1 bit, big-endian, i-signal-type=PRIMITIVE, init-value=0, base-type=boolean, compu-method=CM_IBS_LiquidAlarm, data-constr=DC_IBS_LiquidAlarm, transfer-property=PENDING, to VCU  # EN:Liquid level alarm signal CH:ÒºÎ»±¨¾¯ÐÅºÅ
          signal IBS_AVHStandbySts_oIBS_Status2_oKAMA_FP_EPSChassis1_0303: start 36, 1 bit, big-endian, i-signal-type=PRIMITIVE, init-value=0, base-type=boolean, compu-method=CM_IBS_AVHStandbySts, data-constr=DC_IBS_AVHStandbySts, transfer-property=PENDING, to VCU  # EN:AVH Function Standby CH:AVH ¹¦ÄÜ´ý»ú×´Ì¬
          signal IBS_EPBSwitchPositionValid_oIBS_Status2_oKAMA_FP_EPSChassis1_0303: start 37, 1 bit, big-endian, i-signal-type=PRIMITIVE, init-value=0, base-type=boolean, compu-method=CM_IBS_EPBSwitchPositionValid, data-constr=DC_IBS_EPBSwitchPositionValid, transfer-property=PENDING, to VCU  # EN: EPB Switch Position Valid CH:EPB¿ª¹ØÎ»ÖÃÓÐÐ§
          signal IBS_EPBSwitchPosition_oIBS_Status2_oKAMA_FP_EPSChassis1_0303: start 39, 2 bit, big-endian, i-signal-type=PRIMITIVE, init-value=0, base-type=uint8, compu-method=CM_IBS_EPBSwitchPosition, data-constr=DC_IBS_EPBSwitchPosition, transfer-property=PENDING, to VCU  # EN: EPB Switch Position CH:EPB¿ª¹ØÎ»ÖÃ
          signal IBS_EPBFunctionLamp_oIBS_Status2_oKAMA_FP_EPSChassis1_0303: start 41, 2 bit, big-endian, i-signal-type=PRIMITIVE, init-value=0, base-type=uint8, compu-method=CM_IBS_EPBFunctionLamp, data-constr=DC_IBS_EPBFunctionLamp, transfer-property=PENDING, to VCU  # EN: EPB Function Lamp CH: ¹¦ÄÜÖ¸Ê¾µÆ
          signal MessageCounter_5B_oIBS_Status2_oKAMA_FP_EPSChassis1_0303: start 51, 4 bit, big-endian, i-signal-type=PRIMITIVE, init-value=0, base-type=uint8, compu-method=CM_MessageCounter_5B, data-constr=DC_MessageCounter_5B, transfer-property=PENDING, to VCU
          signal Checksum_5B_oIBS_Status2_oKAMA_FP_EPSChassis1_0303: start 63, 8 bit, big-endian, i-signal-type=PRIMITIVE, init-value=0, base-type=uint8, compu-method=CM_Checksum_5B, data-constr=DC_Checksum_5B, transfer-property=PENDING, to VCU
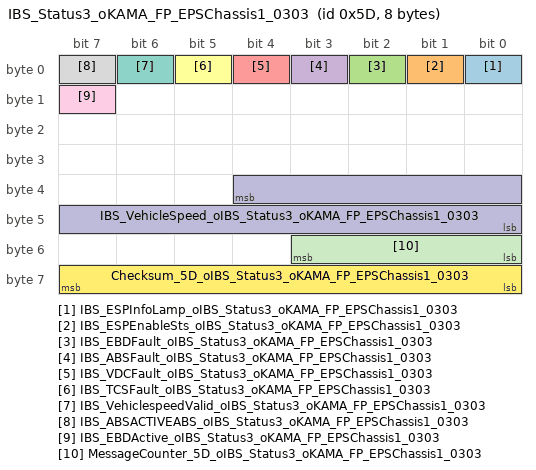
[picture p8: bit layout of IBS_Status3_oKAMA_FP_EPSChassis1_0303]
      frame IBS_Status3_oKAMA_FP_EPSChassis1_0303: id 0x5D, to VCU, frame-length=8, can-addressing-mode=STANDARD
        pdu IBS_Status3_oKAMA_FP_EPSChassis1_0303: length=8, minimum-delay=0, transmission-mode-false-timing=cyclic-timing={time-offset=0, time-period=0.02}, transmission-mode-true-timing=cyclic-timing={time-offset=0, time-period=0.02}, unused-bit-pattern=0
          signal IBS_ESPInfoLamp_oIBS_Status3_oKAMA_FP_EPSChassis1_0303: start 0, 1 bit, big-endian, i-signal-type=PRIMITIVE, init-value=0, base-type=boolean, compu-method=CM_IBS_ESPInfoLamp, data-constr=DC_IBS_ESPInfoLamp, transfer-property=PENDING, to VCU  # EN:Info lamp - Indication that VDC/TCS(engine torque control or brake torque control) system currently performs a brake/engine intervention CH:ESC¹¤×÷Ê±£¬ÒÇ±í½ÓÊÕµ½´ËÐÅºÅ¿ªÊ¼ÉÁË¸
          signal IBS_ESPEnableSts_oIBS_Status3_oKAMA_FP_EPSChassis1_0303: start 1, 1 bit, big-endian, i-signal-type=PRIMITIVE, init-value=0, base-type=boolean, compu-method=CM_IBS_ESPEnableSts, data-constr=DC_IBS_ESPEnableSts, transfer-property=PENDING, to VCU  # EN:ESP function enabled/disabled status CH£ºESC¹¦ÄÜ¿ª¹ØÐÅºÅ
          signal IBS_EBDFault_oIBS_Status3_oKAMA_FP_EPSChassis1_0303: start 2, 1 bit, big-endian, i-signal-type=PRIMITIVE, init-value=0, base-type=boolean, compu-method=CM_IBS_EBDFault, data-constr=DC_IBS_EBDFault, transfer-property=PENDING, to VCU
          signal IBS_ABSFault_oIBS_Status3_oKAMA_FP_EPSChassis1_0303: start 3, 1 bit, big-endian, i-signal-type=PRIMITIVE, init-value=0, base-type=boolean, compu-method=CM_IBS_ABSFault, data-constr=DC_IBS_ABSFault, transfer-property=PENDING, to VCU
          signal IBS_VDCFault_oIBS_Status3_oKAMA_FP_EPSChassis1_0303: start 4, 1 bit, big-endian, i-signal-type=PRIMITIVE, init-value=0, base-type=boolean, compu-method=CM_IBS_VDCFault, data-constr=DC_IBS_VDCFault, transfer-property=PENDING, to VCU  # EN:VDC status valid CH:VDC¹¦ÄÜ¹ÊÕÏ±êÖ¾Î»
          signal IBS_TCSFault_oIBS_Status3_oKAMA_FP_EPSChassis1_0303: start 5, 1 bit, big-endian, i-signal-type=PRIMITIVE, init-value=0, base-type=boolean, compu-method=CM_IBS_TCSFault, data-constr=DC_IBS_TCSFault, transfer-property=PENDING, to VCU  # EN:TCS status valid CH:TCS¹¦ÄÜ¹ÊÕÏ±êÖ¾Î»
          signal IBS_VehiclespeedValid_oIBS_Status3_oKAMA_FP_EPSChassis1_0303: start 6, 1 bit, big-endian, i-signal-type=PRIMITIVE, init-value=0, base-type=boolean, compu-method=CM_IBS_VehiclespeedValid, data-constr=DC_IBS_VehiclespeedValid, transfer-property=PENDING, to VCU
          signal IBS_ABSACTIVEABS_oIBS_Status3_oKAMA_FP_EPSChassis1_0303: start 7, 1 bit, big-endian, i-signal-type=PRIMITIVE, init-value=0, base-type=boolean, compu-method=CM_IBS_ABSACTIVEABS, data-constr=DC_IBS_ABSACTIVEABS, transfer-property=PENDING, to VCU  # EN:indicates ABS intervention active. CH:ABS¼¤»î±êÖ¾Î»£¬±íÊ¾ABS´¦ÓÚ¼¤»î×´Ì¬
          signal IBS_EBDActive_oIBS_Status3_oKAMA_FP_EPSChassis1_0303: start 15, 1 bit, big-endian, i-signal-type=PRIMITIVE, init-value=0, base-type=boolean, compu-method=CM_IBS_EBDActive, data-constr=DC_IBS_EBDActive, transfer-property=PENDING, to VCU  # EN:indicates EBD intervention active. CH:EBD¼¤»î±êÖ¾Î»£¬±íÊ¾EBD´¦ÓÚ¼¤»î×´Ì¬
          signal IBS_VehicleSpeed_oIBS_Status3_oKAMA_FP_EPSChassis1_0303: start 36, 13 bit, big-endian, i-signal-type=PRIMITIVE, init-value=6400, base-type=uint16, compu-method=CM_IBS_VehicleSpeed, data-constr=DC_IBS_VehicleSpeed, unit=U_kmYh, transfer-property=PENDING, to VCU  # EN:Vehicle speed CH:Êä³ö³µËÙÐÅºÅ
          signal MessageCounter_5D_oIBS_Status3_oKAMA_FP_EPSChassis1_0303: start 51, 4 bit, big-endian, i-signal-type=PRIMITIVE, init-value=0, base-type=uint8, compu-method=CM_MessageCounter_5D, data-constr=DC_MessageCounter_5D, transfer-property=PENDING, to VCU
          signal Checksum_5D_oIBS_Status3_oKAMA_FP_EPSChassis1_0303: start 63, 8 bit, big-endian, i-signal-type=PRIMITIVE, init-value=0, base-type=uint8, compu-method=CM_Checksum_5D, data-constr=DC_Checksum_5D, transfer-property=PENDING, to VCU
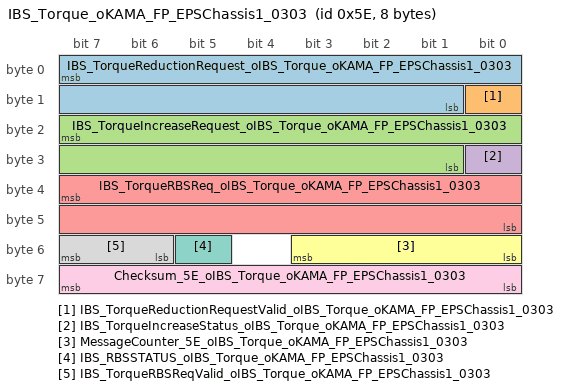
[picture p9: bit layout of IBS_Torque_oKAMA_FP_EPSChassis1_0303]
      frame IBS_Torque_oKAMA_FP_EPSChassis1_0303: id 0x5E, to VCU, frame-length=8, can-addressing-mode=STANDARD
        pdu IBS_Torque_oKAMA_FP_EPSChassis1_0303: length=8, minimum-delay=0, transmission-mode-false-timing=cyclic-timing={time-offset=0, time-period=0.02}, transmission-mode-true-timing=cyclic-timing={time-offset=0, time-period=0.02}, unused-bit-pattern=0
          signal IBS_TorqueReductionRequest_oIBS_Torque_oKAMA_FP_EPSChassis1_0303: start 7, 15 bit, big-endian, i-signal-type=PRIMITIVE, init-value=5400, base-type=uint16, compu-method=CM_IBS_TorqueReductionRequest, data-constr=DC_IBS_TorqueReductionRequest, unit=U_NM, transfer-property=PENDING, to VCU  # EN:engine torque fast reduction request CH:ESCÇëÇó·¢¶¯»ú¿ìËÙ½µÅ¤ÊýÖµ
          signal IBS_TorqueReductionRequestValid_oIBS_Torque_oKAMA_FP_EPSChassis1_0303: start 8, 1 bit, big-endian, i-signal-type=PRIMITIVE, init-value=0, base-type=boolean, compu-method=CM_IBS_TorqueReductionRequestValid, data-constr=DC_IBS_TorqueReductionRequestValid, transfer-property=PENDING, to VCU  # EN£ºEngine torque reduction request status CH:ESCÇëÇó·¢¶¯»úÏìÓ¦½µÅ¤±êÖ¾Î»
          signal IBS_TorqueIncreaseRequest_oIBS_Torque_oKAMA_FP_EPSChassis1_0303: start 23, 15 bit, big-endian, i-signal-type=PRIMITIVE, init-value=5400, base-type=uint16, compu-method=CM_IBS_TorqueIncreaseRequest, data-constr=DC_IBS_TorqueIncreaseRequest, unit=U_NM, transfer-property=PENDING, to VCU  # EN:engine torque increase request CH:ESCÔöÅ¤ÇëÇó
          signal IBS_TorqueIncreaseStatus_oIBS_Torque_oKAMA_FP_EPSChassis1_0303: start 24, 1 bit, big-endian, i-signal-type=PRIMITIVE, init-value=0, base-type=boolean, compu-method=CM_IBS_TorqueIncreaseStatus, data-constr=DC_IBS_TorqueIncreaseStatus, transfer-property=PENDING, to VCU  # EN£ºEngine torque increase request status CH:ESCÇëÇó·¢¶¯»úÏìÓ¦ÔöÅ¤±êÖ¾Î»
          signal IBS_TorqueRBSReq_oIBS_Torque_oKAMA_FP_EPSChassis1_0303: start 39, 16 bit, big-endian, i-signal-type=PRIMITIVE, init-value=32768, base-type=uint16, compu-method=CM_IBS_TorqueRBSReq, data-constr=DC_IBS_TorqueRBSReq, unit=U_Nm, transfer-property=PENDING, to VCU  # EN:Motor torque demand CH:µç»ú×ª¾ØÐèÇó
          signal MessageCounter_5E_oIBS_Torque_oKAMA_FP_EPSChassis1_0303: start 51, 4 bit, big-endian, i-signal-type=PRIMITIVE, init-value=0, base-type=uint8, compu-method=CM_MessageCounter_5E, data-constr=DC_MessageCounter_5E, transfer-property=PENDING, to VCU
          signal IBS_RBSSTATUS_oIBS_Torque_oKAMA_FP_EPSChassis1_0303: start 53, 1 bit, big-endian, i-signal-type=PRIMITIVE, init-value=0, base-type=boolean, compu-method=CM_IBS_RBSSTATUS, data-constr=DC_IBS_RBSSTATUS, transfer-property=PENDING, to VCU  # EN:Energy recovery status CH:ÄÜÁ¿»ØÊÕ×´Ì¬±êÖ¾
          signal IBS_TorqueRBSReqValid_oIBS_Torque_oKAMA_FP_EPSChassis1_0303: start 55, 2 bit, big-endian, i-signal-type=PRIMITIVE, init-value=0, base-type=uint8, compu-method=CM_IBS_TorqueRBSReqValid, data-constr=DC_IBS_TorqueRBSReqValid, transfer-property=PENDING, to VCU  # EN:Motor torque demand valid CH:µç»ú×ª¾ØÐèÇóÓÐÐ§×´Ì¬
          signal Checksum_5E_oIBS_Torque_oKAMA_FP_EPSChassis1_0303: start 63, 8 bit, big-endian, i-signal-type=PRIMITIVE, init-value=0, base-type=uint8, compu-method=CM_Checksum_5E, data-constr=DC_Checksum_5E, transfer-property=PENDING, to VCU
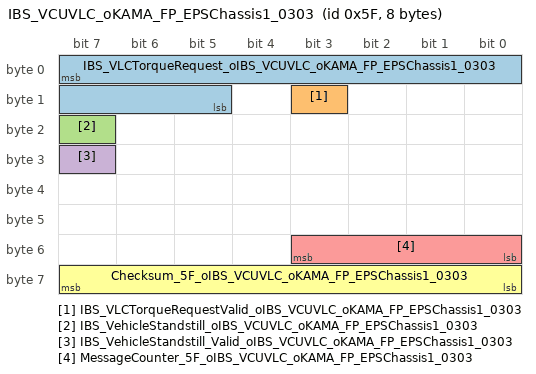
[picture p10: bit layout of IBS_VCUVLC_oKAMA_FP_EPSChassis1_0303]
      frame IBS_VCUVLC_oKAMA_FP_EPSChassis1_0303: id 0x5F, to VCU, frame-length=8, can-addressing-mode=STANDARD
        pdu IBS_VCUVLC_oKAMA_FP_EPSChassis1_0303: length=8, minimum-delay=0, transmission-mode-false-timing=cyclic-timing={time-offset=0, time-period=0.02}, transmission-mode-true-timing=cyclic-timing={time-offset=0, time-period=0.02}, unused-bit-pattern=0
          signal IBS_VLCTorqueRequest_oIBS_VCUVLC_oKAMA_FP_EPSChassis1_0303: start 7, 11 bit, big-endian, i-signal-type=PRIMITIVE, init-value=1024, base-type=uint16, compu-method=CM_IBS_VLCTorqueRequest, data-constr=DC_IBS_VLCTorqueRequest, transfer-property=PENDING, to VCU  # VLC Torque Request Value
          signal IBS_VLCTorqueRequestValid_oIBS_VCUVLC_oKAMA_FP_EPSChassis1_0303: start 11, 1 bit, big-endian, i-signal-type=PRIMITIVE, init-value=0, base-type=boolean, compu-method=CM_IBS_VLCTorqueRequestValid, data-constr=DC_IBS_VLCTorqueRequestValid, transfer-property=PENDING, to VCU  # VLC Torque Request active
          signal IBS_VehicleStandstill_oIBS_VCUVLC_oKAMA_FP_EPSChassis1_0303: start 23, 1 bit, big-endian, i-signal-type=PRIMITIVE, init-value=0, base-type=boolean, compu-method=CM_IBS_VehicleStandstill, data-constr=DC_IBS_VehicleStandstill, transfer-property=PENDING, to VCU
          signal IBS_VehicleStandstill_Valid_oIBS_VCUVLC_oKAMA_FP_EPSChassis1_0303: start 31, 1 bit, big-endian, i-signal-type=PRIMITIVE, init-value=0, base-type=boolean, compu-method=CM_IBS_VehicleStandstill_Valid, data-constr=DC_IBS_VehicleStandstill_Valid, transfer-property=PENDING, to VCU
          signal MessageCounter_5F_oIBS_VCUVLC_oKAMA_FP_EPSChassis1_0303: start 51, 4 bit, big-endian, i-signal-type=PRIMITIVE, init-value=0, base-type=uint8, compu-method=CM_MessageCounter_5F, data-constr=DC_MessageCounter_5F, transfer-property=PENDING, to VCU
          signal Checksum_5F_oIBS_VCUVLC_oKAMA_FP_EPSChassis1_0303: start 63, 8 bit, big-endian, i-signal-type=PRIMITIVE, init-value=0, base-type=uint8, compu-method=CM_Checksum_5F, data-constr=DC_Checksum_5F, transfer-property=PENDING, to VCU
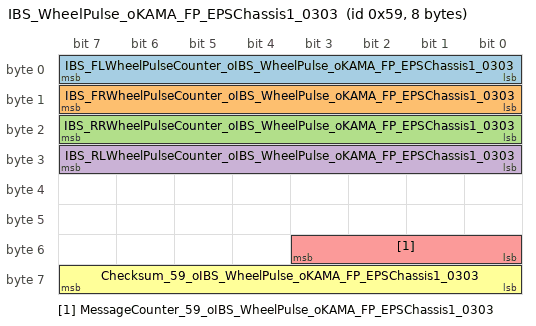
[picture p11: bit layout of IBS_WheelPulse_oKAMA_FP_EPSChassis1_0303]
      frame IBS_WheelPulse_oKAMA_FP_EPSChassis1_0303: id 0x59, to VCU, frame-length=8, can-addressing-mode=STANDARD
        pdu IBS_WheelPulse_oKAMA_FP_EPSChassis1_0303: length=8, minimum-delay=0, transmission-mode-false-timing=cyclic-timing={time-offset=0, time-period=0.02}, transmission-mode-true-timing=cyclic-timing={time-offset=0, time-period=0.02}, unused-bit-pattern=0
          signal IBS_FLWheelPulseCounter_oIBS_WheelPulse_oKAMA_FP_EPSChassis1_0303: start 7, 8 bit, big-endian, i-signal-type=PRIMITIVE, init-value=0, base-type=uint8, compu-method=CM_IBS_FLWheelPulseCounter, data-constr=DC_IBS_FLWheelPulseCounter, transfer-property=PENDING, to VCU  # EN:Front left wheel speed pulse CH£º×óÇ°ÂÖÂö³å¼ÆÊý
          signal IBS_FRWheelPulseCounter_oIBS_WheelPulse_oKAMA_FP_EPSChassis1_0303: start 15, 8 bit, big-endian, i-signal-type=PRIMITIVE, init-value=0, base-type=uint8, compu-method=CM_IBS_FRWheelPulseCounter, data-constr=DC_IBS_FRWheelPulseCounter, transfer-property=PENDING, to VCU  # EN:Front right wheel speed pulse CH£ºÓÒÇ°ÂÖÂö³å¼ÆÊý
          signal IBS_RRWheelPulseCounter_oIBS_WheelPulse_oKAMA_FP_EPSChassis1_0303: start 23, 8 bit, big-endian, i-signal-type=PRIMITIVE, init-value=0, base-type=uint8, compu-method=CM_IBS_RRWheelPulseCounter, data-constr=DC_IBS_RRWheelPulseCounter, transfer-property=PENDING, to VCU  # EN:Rear right wheel speed pulse CH£ºÓÒºóÂÖÂö³å¼ÆÊý
          signal IBS_RLWheelPulseCounter_oIBS_WheelPulse_oKAMA_FP_EPSChassis1_0303: start 31, 8 bit, big-endian, i-signal-type=PRIMITIVE, init-value=0, base-type=uint8, compu-method=CM_IBS_RLWheelPulseCounter, data-constr=DC_IBS_RLWheelPulseCounter, transfer-property=PENDING, to VCU  # EN:Rear left wheel speed pulse CH£º×óºóÂÖÂö³å¼ÆÊý
          signal MessageCounter_59_oIBS_WheelPulse_oKAMA_FP_EPSChassis1_0303: start 51, 4 bit, big-endian, i-signal-type=PRIMITIVE, init-value=0, base-type=uint8, compu-method=CM_MessageCounter_59, data-constr=DC_MessageCounter_59, transfer-property=PENDING, to VCU
          signal Checksum_59_oIBS_WheelPulse_oKAMA_FP_EPSChassis1_0303: start 63, 8 bit, big-endian, i-signal-type=PRIMITIVE, init-value=0, base-type=uint8, compu-method=CM_Checksum_59, data-constr=DC_Checksum_59, transfer-property=PENDING, to VCU
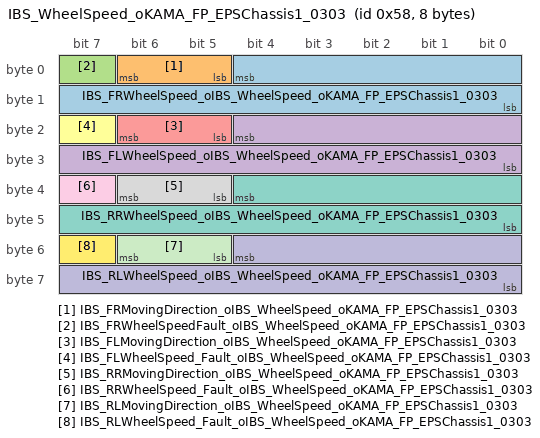
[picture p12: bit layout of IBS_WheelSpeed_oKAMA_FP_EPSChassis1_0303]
      frame IBS_WheelSpeed_oKAMA_FP_EPSChassis1_0303: id 0x58, to VCU, frame-length=8, can-addressing-mode=STANDARD
        pdu IBS_WheelSpeed_oKAMA_FP_EPSChassis1_0303: length=8, minimum-delay=0, transmission-mode-false-timing=cyclic-timing={time-offset=0, time-period=0.02}, transmission-mode-true-timing=cyclic-timing={time-offset=0, time-period=0.02}, unused-bit-pattern=0
          signal IBS_FRWheelSpeed_oIBS_WheelSpeed_oKAMA_FP_EPSChassis1_0303: start 4, 13 bit, big-endian, i-signal-type=PRIMITIVE, init-value=0, base-type=uint16, compu-method=CM_IBS_FRWheelSpeed, data-constr=DC_IBS_FRWheelSpeed, unit=U_kmYh, transfer-property=PENDING, to VCU  # EN: Front right wheel speed CH:ÓÒÇ°ÂÖÂÖËÙÐÅºÅ
          signal IBS_FRMovingDirection_oIBS_WheelSpeed_oKAMA_FP_EPSChassis1_0303: start 6, 2 bit, big-endian, i-signal-type=PRIMITIVE, init-value=0, base-type=uint8, compu-method=CM_IBS_FRMovingDirection, data-constr=DC_IBS_FRMovingDirection, transfer-property=PENDING, to VCU
          signal IBS_FRWheelSpeedFault_oIBS_WheelSpeed_oKAMA_FP_EPSChassis1_0303: start 7, 1 bit, big-endian, i-signal-type=PRIMITIVE, init-value=0, base-type=boolean, compu-method=CM_IBS_FRWheelSpeedFault, data-constr=DC_IBS_FRWheelSpeedFault, transfer-property=PENDING, to VCU  # EN:Front right wheel speed signal valid CH:ÓÒÇ°ÂÖÂÖËÙÓÐÐ§ÐÅºÅ
          signal IBS_FLWheelSpeed_oIBS_WheelSpeed_oKAMA_FP_EPSChassis1_0303: start 20, 13 bit, big-endian, i-signal-type=PRIMITIVE, init-value=0, base-type=uint16, compu-method=CM_IBS_FLWheelSpeed, data-constr=DC_IBS_FLWheelSpeed, unit=U_kmYh, transfer-property=PENDING, to VCU  # EN:Front left wheel speed CH:×óÇ°ÂÖÂÖËÙÐÅºÅ
          signal IBS_FLMovingDirection_oIBS_WheelSpeed_oKAMA_FP_EPSChassis1_0303: start 22, 2 bit, big-endian, i-signal-type=PRIMITIVE, init-value=0, base-type=uint8, compu-method=CM_IBS_FLMovingDirection, data-constr=DC_IBS_FLMovingDirection, transfer-property=PENDING, to VCU
          signal IBS_FLWheelSpeed_Fault_oIBS_WheelSpeed_oKAMA_FP_EPSChassis1_0303: start 23, 1 bit, big-endian, i-signal-type=PRIMITIVE, init-value=0, base-type=boolean, compu-method=CM_IBS_FLWheelSpeed_Fault, data-constr=DC_IBS_FLWheelSpeed_Fault, transfer-property=PENDING, to VCU  # EN:Front left wheel speed signal valid CH:×óÇ°ÂÖÂÖËÙÓÐÐ§ÐÅºÅ
          signal IBS_RRWheelSpeed_oIBS_WheelSpeed_oKAMA_FP_EPSChassis1_0303: start 36, 13 bit, big-endian, i-signal-type=PRIMITIVE, init-value=0, base-type=uint16, compu-method=CM_IBS_RRWheelSpeed, data-constr=DC_IBS_RRWheelSpeed, unit=U_kmYh, transfer-property=PENDING, to VCU  # EN:Rear right wheel speed CH:ÓÒºóÂÖÂÖËÙÐÅºÅ
          signal IBS_RRMovingDirection_oIBS_WheelSpeed_oKAMA_FP_EPSChassis1_0303: start 38, 2 bit, big-endian, i-signal-type=PRIMITIVE, init-value=0, base-type=uint8, compu-method=CM_IBS_RRMovingDirection, data-constr=DC_IBS_RRMovingDirection, transfer-property=PENDING, to VCU
          signal IBS_RRWheelSpeed_Fault_oIBS_WheelSpeed_oKAMA_FP_EPSChassis1_0303: start 39, 1 bit, big-endian, i-signal-type=PRIMITIVE, init-value=0, base-type=boolean, compu-method=CM_IBS_RRWheelSpeed_Fault, data-constr=DC_IBS_RRWheelSpeed_Fault, transfer-property=PENDING, to VCU  # EN:Rear right wheel speed signal valid CH:ÓÒºóÂÖÂÖËÙÓÐÐ§ÐÅºÅ
          signal IBS_RLWheelSpeed_oIBS_WheelSpeed_oKAMA_FP_EPSChassis1_0303: start 52, 13 bit, big-endian, i-signal-type=PRIMITIVE, init-value=0, base-type=uint16, compu-method=CM_IBS_RLWheelSpeed, data-constr=DC_IBS_RLWheelSpeed, unit=U_kmYh, transfer-property=PENDING, to VCU  # EN:Rear left wheel speed CH:×óºóÂÖÂÖËÙÐÅºÅ
          signal IBS_RLMovingDirection_oIBS_WheelSpeed_oKAMA_FP_EPSChassis1_0303: start 54, 2 bit, big-endian, i-signal-type=PRIMITIVE, init-value=0, base-type=uint8, compu-method=CM_IBS_RLMovingDirection, data-constr=DC_IBS_RLMovingDirection, transfer-property=PENDING, to VCU
          signal IBS_RLWheelSpeed_Fault_oIBS_WheelSpeed_oKAMA_FP_EPSChassis1_0303: start 55, 1 bit, big-endian, i-signal-type=PRIMITIVE, init-value=0, base-type=boolean, compu-method=CM_IBS_RLWheelSpeed_Fault, data-constr=DC_IBS_RLWheelSpeed_Fault, transfer-property=PENDING, to VCU  # EN:Rear left wheel speed signal valid CH:×óºóÂÖÂÖËÙÓÐÐ§ÐÅºÅ
      frame IBS1_acceleration_oKAMA_FP_EPSChassis1_0303: id 0x5C, to VCU, frame-length=8, can-addressing-mode=STANDARD
        pdu IBS1_acceleration_oKAMA_FP_EPSChassis1_0303: length=8, minimum-delay=0, transmission-mode-false-timing=cyclic-timing={time-offset=0, time-period=0.02}, transmission-mode-true-timing=cyclic-timing={time-offset=0, time-period=0.02}, unused-bit-pattern=0
          signal IBS_ESCYawRate_oIBS1_acceleration_oKAMA_FP_EPSChassis1_0303: start 7, 16 bit, big-endian, i-signal-type=PRIMITIVE, init-value=32768, base-type=uint16, compu-method=CM_IBS_ESCYawRate, data-constr=DC_IBS_ESCYawRate, unit=U_Ys, transfer-property=PENDING, to VCU  # EN:yaw rate CH:ÓÉESC×ª·¢YRSºá°Ú½ÇËÙ¶ÈÐÅºÅ
          signal IBS_ESCLateralAccle_oIBS1_acceleration_oKAMA_FP_EPSChassis1_0303: start 23, 16 bit, big-endian, i-signal-type=PRIMITIVE, init-value=32784.9293563579, base-type=uint16, compu-method=CM_IBS_ESCLateralAccle, data-constr=DC_IBS_ESCLateralAccle, unit=U_gYdigit, transfer-property=PENDING, to VCU  # EN:Lateral acceleration CH:ÓÉESC×ª·¢YRS²àÏò¼ÓËÙ¶ÈÐÅºÅ
          signal IBS_ESCLongitudinalAccle_oIBS1_acceleration_oKAMA_FP_EPSChassis1_0303: start 39, 16 bit, big-endian, i-signal-type=PRIMITIVE, init-value=32784.9293563579, base-type=uint16, compu-method=CM_IBS_ESCLongitudinalAccle, data-constr=DC_IBS_ESCLongitudinalAccle, unit=U_gYdigit, transfer-property=PENDING, to VCU  # EN:Longitudinal acceleration CH:ÓÉESC×ª·¢YRS×ÝÏò¼ÓËÙ¶ÈÐÅºÅ
          signal MessageCounter_5C_oIBS1_acceleration_oKAMA_FP_EPSChassis1_0303: start 51, 4 bit, big-endian, i-signal-type=PRIMITIVE, init-value=0, base-type=uint8, compu-method=CM_MessageCounter_5C, data-constr=DC_MessageCounter_5C, transfer-property=PENDING, to VCU
          signal Checksum_5C_oIBS1_acceleration_oKAMA_FP_EPSChassis1_0303: start 63, 8 bit, big-endian, i-signal-type=PRIMITIVE, init-value=0, base-type=uint8, compu-method=CM_Checksum_5C, data-constr=DC_Checksum_5C, transfer-property=PENDING, to VCU
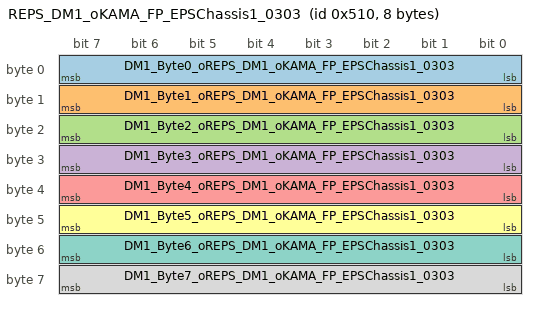
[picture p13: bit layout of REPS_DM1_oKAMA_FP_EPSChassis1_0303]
      frame REPS_DM1_oKAMA_FP_EPSChassis1_0303: id 0x510, to VCU, frame-length=8, can-addressing-mode=STANDARD
        pdu REPS_DM1_oKAMA_FP_EPSChassis1_0303: length=8, minimum-delay=0, transmission-mode-false-timing=cyclic-timing={time-offset=0, time-period=0.1}, transmission-mode-true-timing=cyclic-timing={time-offset=0, time-period=0.1}, unused-bit-pattern=0
          signal DM1_Byte0_oREPS_DM1_oKAMA_FP_EPSChassis1_0303: start 7, 8 bit, big-endian, i-signal-type=PRIMITIVE, init-value=0, base-type=uint8, compu-method=CM_DM1_Byte0, data-constr=DC_DM1_Byte0, transfer-property=PENDING, to VCU
          signal DM1_Byte1_oREPS_DM1_oKAMA_FP_EPSChassis1_0303: start 15, 8 bit, big-endian, i-signal-type=PRIMITIVE, init-value=0, base-type=uint8, compu-method=CM_DM1_Byte1, data-constr=DC_DM1_Byte1, transfer-property=PENDING, to VCU
          signal DM1_Byte2_oREPS_DM1_oKAMA_FP_EPSChassis1_0303: start 23, 8 bit, big-endian, i-signal-type=PRIMITIVE, init-value=0, base-type=uint8, compu-method=CM_DM1_Byte2, data-constr=DC_DM1_Byte2, transfer-property=PENDING, to VCU
          signal DM1_Byte3_oREPS_DM1_oKAMA_FP_EPSChassis1_0303: start 31, 8 bit, big-endian, i-signal-type=PRIMITIVE, init-value=0, base-type=uint8, compu-method=CM_DM1_Byte3, data-constr=DC_DM1_Byte3, transfer-property=PENDING, to VCU
          signal DM1_Byte4_oREPS_DM1_oKAMA_FP_EPSChassis1_0303: start 39, 8 bit, big-endian, i-signal-type=PRIMITIVE, init-value=0, base-type=uint8, compu-method=CM_DM1_Byte4, data-constr=DC_DM1_Byte4, transfer-property=PENDING, to VCU
          signal DM1_Byte5_oREPS_DM1_oKAMA_FP_EPSChassis1_0303: start 47, 8 bit, big-endian, i-signal-type=PRIMITIVE, init-value=0, base-type=uint8, compu-method=CM_DM1_Byte5, data-constr=DC_DM1_Byte5, transfer-property=PENDING, to VCU
          signal DM1_Byte6_oREPS_DM1_oKAMA_FP_EPSChassis1_0303: start 55, 8 bit, big-endian, i-signal-type=PRIMITIVE, init-value=0, base-type=uint8, compu-method=CM_DM1_Byte6, data-constr=DC_DM1_Byte6, transfer-property=PENDING, to VCU
          signal DM1_Byte7_oREPS_DM1_oKAMA_FP_EPSChassis1_0303: start 63, 8 bit, big-endian, i-signal-type=PRIMITIVE, init-value=0, base-type=uint8, compu-method=CM_DM1_Byte7, data-constr=DC_DM1_Byte7, transfer-property=PENDING, to VCU
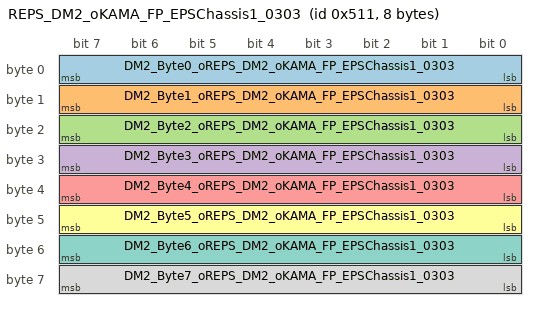
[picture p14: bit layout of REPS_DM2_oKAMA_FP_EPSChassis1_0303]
      frame REPS_DM2_oKAMA_FP_EPSChassis1_0303: id 0x511, to VCU, frame-length=8, can-addressing-mode=STANDARD
        pdu REPS_DM2_oKAMA_FP_EPSChassis1_0303: length=8, minimum-delay=0, transmission-mode-false-timing=cyclic-timing={time-offset=0, time-period=0.1}, transmission-mode-true-timing=cyclic-timing={time-offset=0, time-period=0.1}, unused-bit-pattern=0
          signal DM2_Byte0_oREPS_DM2_oKAMA_FP_EPSChassis1_0303: start 7, 8 bit, big-endian, i-signal-type=PRIMITIVE, init-value=0, base-type=uint8, compu-method=CM_DM2_Byte0, data-constr=DC_DM2_Byte0, transfer-property=PENDING, to VCU
          signal DM2_Byte1_oREPS_DM2_oKAMA_FP_EPSChassis1_0303: start 15, 8 bit, big-endian, i-signal-type=PRIMITIVE, init-value=0, base-type=uint8, compu-method=CM_DM2_Byte1, data-constr=DC_DM2_Byte1, transfer-property=PENDING, to VCU
          signal DM2_Byte2_oREPS_DM2_oKAMA_FP_EPSChassis1_0303: start 23, 8 bit, big-endian, i-signal-type=PRIMITIVE, init-value=0, base-type=uint8, compu-method=CM_DM2_Byte2, data-constr=DC_DM2_Byte2, transfer-property=PENDING, to VCU
          signal DM2_Byte3_oREPS_DM2_oKAMA_FP_EPSChassis1_0303: start 31, 8 bit, big-endian, i-signal-type=PRIMITIVE, init-value=0, base-type=uint8, compu-method=CM_DM2_Byte3, data-constr=DC_DM2_Byte3, transfer-property=PENDING, to VCU
          signal DM2_Byte4_oREPS_DM2_oKAMA_FP_EPSChassis1_0303: start 39, 8 bit, big-endian, i-signal-type=PRIMITIVE, init-value=0, base-type=uint8, compu-method=CM_DM2_Byte4, data-constr=DC_DM2_Byte4, transfer-property=PENDING, to VCU
          signal DM2_Byte5_oREPS_DM2_oKAMA_FP_EPSChassis1_0303: start 47, 8 bit, big-endian, i-signal-type=PRIMITIVE, init-value=0, base-type=uint8, compu-method=CM_DM2_Byte5, data-constr=DC_DM2_Byte5, transfer-property=PENDING, to VCU
          signal DM2_Byte6_oREPS_DM2_oKAMA_FP_EPSChassis1_0303: start 55, 8 bit, big-endian, i-signal-type=PRIMITIVE, init-value=0, base-type=uint8, compu-method=CM_DM2_Byte6, data-constr=DC_DM2_Byte6, transfer-property=PENDING, to VCU
          signal DM2_Byte7_oREPS_DM2_oKAMA_FP_EPSChassis1_0303: start 63, 8 bit, big-endian, i-signal-type=PRIMITIVE, init-value=0, base-type=uint8, compu-method=CM_DM2_Byte7, data-constr=DC_DM2_Byte7, transfer-property=PENDING, to VCU
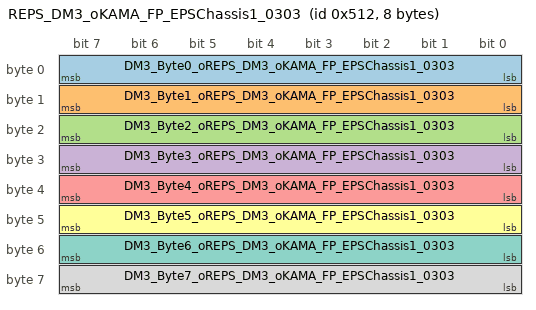
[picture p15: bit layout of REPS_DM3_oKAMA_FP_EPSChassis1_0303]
      frame REPS_DM3_oKAMA_FP_EPSChassis1_0303: id 0x512, to VCU, frame-length=8, can-addressing-mode=STANDARD
        pdu REPS_DM3_oKAMA_FP_EPSChassis1_0303: length=8, minimum-delay=0, transmission-mode-false-timing=cyclic-timing={time-offset=0, time-period=0.1}, transmission-mode-true-timing=cyclic-timing={time-offset=0, time-period=0.1}, unused-bit-pattern=0
          signal DM3_Byte0_oREPS_DM3_oKAMA_FP_EPSChassis1_0303: start 7, 8 bit, big-endian, i-signal-type=PRIMITIVE, init-value=0, base-type=uint8, compu-method=CM_DM3_Byte0, data-constr=DC_DM3_Byte0, transfer-property=PENDING, to VCU
          signal DM3_Byte1_oREPS_DM3_oKAMA_FP_EPSChassis1_0303: start 15, 8 bit, big-endian, i-signal-type=PRIMITIVE, init-value=0, base-type=uint8, compu-method=CM_DM3_Byte1, data-constr=DC_DM3_Byte1, transfer-property=PENDING, to VCU
          signal DM3_Byte2_oREPS_DM3_oKAMA_FP_EPSChassis1_0303: start 23, 8 bit, big-endian, i-signal-type=PRIMITIVE, init-value=0, base-type=uint8, compu-method=CM_DM3_Byte2, data-constr=DC_DM3_Byte2, transfer-property=PENDING, to VCU
          signal DM3_Byte3_oREPS_DM3_oKAMA_FP_EPSChassis1_0303: start 31, 8 bit, big-endian, i-signal-type=PRIMITIVE, init-value=0, base-type=uint8, compu-method=CM_DM3_Byte3, data-constr=DC_DM3_Byte3, transfer-property=PENDING, to VCU
          signal DM3_Byte4_oREPS_DM3_oKAMA_FP_EPSChassis1_0303: start 39, 8 bit, big-endian, i-signal-type=PRIMITIVE, init-value=0, base-type=uint8, compu-method=CM_DM3_Byte4, data-constr=DC_DM3_Byte4, transfer-property=PENDING, to VCU
          signal DM3_Byte5_oREPS_DM3_oKAMA_FP_EPSChassis1_0303: start 47, 8 bit, big-endian, i-signal-type=PRIMITIVE, init-value=0, base-type=uint8, compu-method=CM_DM3_Byte5, data-constr=DC_DM3_Byte5, transfer-property=PENDING, to VCU
          signal DM3_Byte6_oREPS_DM3_oKAMA_FP_EPSChassis1_0303: start 55, 8 bit, big-endian, i-signal-type=PRIMITIVE, init-value=0, base-type=uint8, compu-method=CM_DM3_Byte6, data-constr=DC_DM3_Byte6, transfer-property=PENDING, to VCU
          signal DM3_Byte7_oREPS_DM3_oKAMA_FP_EPSChassis1_0303: start 63, 8 bit, big-endian, i-signal-type=PRIMITIVE, init-value=0, base-type=uint8, compu-method=CM_DM3_Byte7, data-constr=DC_DM3_Byte7, transfer-property=PENDING, to VCU
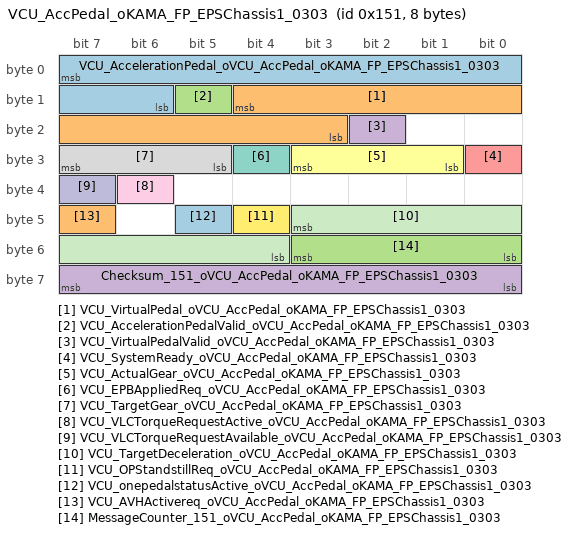
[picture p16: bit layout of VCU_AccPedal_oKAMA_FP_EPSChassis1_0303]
      frame VCU_AccPedal_oKAMA_FP_EPSChassis1_0303: id 0x151, from VCU, frame-length=8, can-addressing-mode=STANDARD
        pdu VCU_AccPedal_oKAMA_FP_EPSChassis1_0303: length=8, minimum-delay=0, transmission-mode-false-timing=cyclic-timing={time-offset=0, time-period=0.02}, transmission-mode-true-timing=cyclic-timing={time-offset=0, time-period=0.02}, unused-bit-pattern=0
          signal VCU_AccelerationPedal_oVCU_AccPedal_oKAMA_FP_EPSChassis1_0303: start 7, 10 bit, big-endian, i-signal-type=PRIMITIVE, init-value=0, base-type=uint16, compu-method=CM_VCU_AccelerationPedal, data-constr=DC_VCU_AccelerationPedal, unit=U_p, transfer-property=PENDING
          signal VCU_VirtualPedal_oVCU_AccPedal_oKAMA_FP_EPSChassis1_0303: start 12, 10 bit, big-endian, i-signal-type=PRIMITIVE, init-value=0, base-type=uint16, compu-method=CM_VCU_VirtualPedal, data-constr=DC_VCU_VirtualPedal, unit=U_p, transfer-property=PENDING
          signal VCU_AccelerationPedalValid_oVCU_AccPedal_oKAMA_FP_EPSChassis1_0303: start 13, 1 bit, big-endian, i-signal-type=PRIMITIVE, init-value=0, base-type=boolean, compu-method=CM_VCU_AccelerationPedalValid, data-constr=DC_VCU_AccelerationPedalValid, transfer-property=PENDING
          signal VCU_VirtualPedalValid_oVCU_AccPedal_oKAMA_FP_EPSChassis1_0303: start 18, 1 bit, big-endian, i-signal-type=PRIMITIVE, init-value=0, base-type=boolean, compu-method=CM_VCU_VirtualPedalValid, data-constr=DC_VCU_VirtualPedalValid, transfer-property=PENDING
          signal VCU_SystemReady_oVCU_AccPedal_oKAMA_FP_EPSChassis1_0303: start 24, 1 bit, big-endian, i-signal-type=PRIMITIVE, init-value=0, base-type=boolean, compu-method=CM_VCU_SystemReady, data-constr=DC_VCU_SystemReady, transfer-property=PENDING
          signal VCU_ActualGear_oVCU_AccPedal_oKAMA_FP_EPSChassis1_0303: start 27, 3 bit, big-endian, i-signal-type=PRIMITIVE, init-value=0, base-type=uint8, compu-method=CM_VCU_ActualGear, data-constr=DC_VCU_ActualGear, transfer-property=PENDING
          signal VCU_EPBAppliedReq_oVCU_AccPedal_oKAMA_FP_EPSChassis1_0303: start 28, 1 bit, big-endian, i-signal-type=PRIMITIVE, init-value=0, base-type=boolean, compu-method=CM_VCU_EPBAppliedReq, data-constr=DC_VCU_EPBAppliedReq, transfer-property=PENDING
          signal VCU_TargetGear_oVCU_AccPedal_oKAMA_FP_EPSChassis1_0303: start 31, 3 bit, big-endian, i-signal-type=PRIMITIVE, init-value=0, base-type=uint8, compu-method=CM_VCU_TargetGear, data-constr=DC_VCU_TargetGear, transfer-property=PENDING
          signal VCU_VLCTorqueRequestActive_oVCU_AccPedal_oKAMA_FP_EPSChassis1_0303: start 38, 1 bit, big-endian, i-signal-type=PRIMITIVE, init-value=0, base-type=boolean, compu-method=CM_VCU_VLCTorqueRequestActive, data-constr=DC_VCU_VLCTorqueRequestActive, transfer-property=PENDING  # VCUÏìÓ¦VLCÅ¤¾ØÇëÇó¹¦ÄÜÊÇ·ñ¼¤»î
          signal VCU_VLCTorqueRequestAvailable_oVCU_AccPedal_oKAMA_FP_EPSChassis1_0303: start 39, 1 bit, big-endian, i-signal-type=PRIMITIVE, init-value=0, base-type=boolean, compu-method=CM_VCU_VLCTorqueRequestAvailable, data-constr=DC_VCU_VLCTorqueRequestAvailable, transfer-property=PENDING  # VCUÏìÓ¦VLCÅ¤¾ØÇëÇóÊÇ·ñ¿ÉÓÃ
          signal VCU_TargetDeceleration_oVCU_AccPedal_oKAMA_FP_EPSChassis1_0303: start 43, 8 bit, big-endian, i-signal-type=PRIMITIVE, init-value=140, base-type=uint8, compu-method=CM_VCU_TargetDeceleration, data-constr=DC_VCU_TargetDeceleration, unit=U_mYsX2, transfer-property=PENDING
          signal VCU_OPStandstillReq_oVCU_AccPedal_oKAMA_FP_EPSChassis1_0303: start 44, 1 bit, big-endian, i-signal-type=PRIMITIVE, init-value=0, base-type=boolean, compu-method=CM_VCU_OPStandstillReq, data-constr=DC_VCU_OPStandstillReq, transfer-property=PENDING
          signal VCU_onepedalstatusActive_oVCU_AccPedal_oKAMA_FP_EPSChassis1_0303: start 45, 1 bit, big-endian, i-signal-type=PRIMITIVE, init-value=0, base-type=boolean, compu-method=CM_VCU_onepedalstatusActive, data-constr=DC_VCU_onepedalstatusActive, transfer-property=PENDING
          signal VCU_AVHActivereq_oVCU_AccPedal_oKAMA_FP_EPSChassis1_0303: start 47, 1 bit, big-endian, i-signal-type=PRIMITIVE, init-value=0, base-type=boolean, compu-method=CM_VCU_AVHActivereq, data-constr=DC_VCU_AVHActivereq, transfer-property=PENDING
          signal MessageCounter_151_oVCU_AccPedal_oKAMA_FP_EPSChassis1_0303: start 51, 4 bit, big-endian, i-signal-type=PRIMITIVE, init-value=0, base-type=uint8, compu-method=CM_MessageCounter_151, data-constr=DC_MessageCounter_151, transfer-property=PENDING
          signal Checksum_151_oVCU_AccPedal_oKAMA_FP_EPSChassis1_0303: start 63, 8 bit, big-endian, i-signal-type=PRIMITIVE, init-value=0, base-type=uint8, compu-method=CM_Checksum_151, data-constr=DC_Checksum_151, transfer-property=PENDING
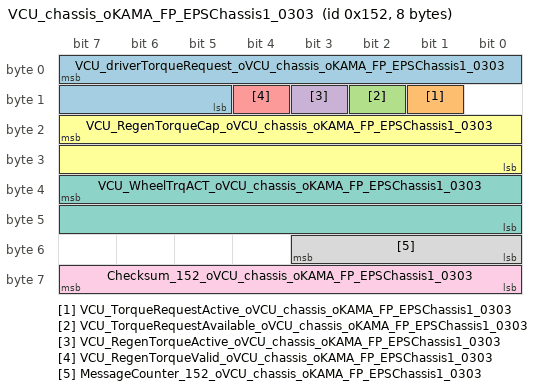
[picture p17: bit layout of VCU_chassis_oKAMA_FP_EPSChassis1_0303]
      frame VCU_chassis_oKAMA_FP_EPSChassis1_0303: id 0x152, from VCU, frame-length=8, can-addressing-mode=STANDARD
        pdu VCU_chassis_oKAMA_FP_EPSChassis1_0303: length=8, minimum-delay=0, transmission-mode-false-timing=cyclic-timing={time-offset=0, time-period=0.02}, transmission-mode-true-timing=cyclic-timing={time-offset=0, time-period=0.02}, unused-bit-pattern=0
          signal VCU_driverTorqueRequest_oVCU_chassis_oKAMA_FP_EPSChassis1_0303: start 7, 11 bit, big-endian, i-signal-type=PRIMITIVE, init-value=1023, base-type=uint16, compu-method=CM_VCU_driverTorqueRequest, data-constr=DC_VCU_driverTorqueRequest, unit=U_Nm, transfer-property=PENDING  # ¼ÝÊ»Ô±ÐèÇóÅ¤¾Ø
          signal VCU_TorqueRequestActive_oVCU_chassis_oKAMA_FP_EPSChassis1_0303: start 9, 1 bit, big-endian, i-signal-type=PRIMITIVE, init-value=0, base-type=boolean, compu-method=CM_VCU_TorqueRequestActive, data-constr=DC_VCU_TorqueRequestActive, transfer-property=PENDING  # VCUÏìÓ¦Íâ²¿Å¤¾ØÇëÇó¹¦ÄÜÊÇ·ñ¼¤»î
          signal VCU_TorqueRequestAvailable_oVCU_chassis_oKAMA_FP_EPSChassis1_0303: start 10, 1 bit, big-endian, i-signal-type=PRIMITIVE, init-value=0, base-type=boolean, compu-method=CM_VCU_TorqueRequestAvailable, data-constr=DC_VCU_TorqueRequestAvailable, transfer-property=PENDING  # VCUÏìÓ¦Íâ²¿Å¤¾ØÇëÇóÊÇ·ñ¿ÉÓÃ
          signal VCU_RegenTorqueActive_oVCU_chassis_oKAMA_FP_EPSChassis1_0303: start 11, 1 bit, big-endian, i-signal-type=PRIMITIVE, init-value=0, base-type=boolean, compu-method=CM_VCU_RegenTorqueActive, data-constr=DC_VCU_RegenTorqueActive, transfer-property=PENDING  # µç»ú×î´óÖÆ¶¯»ØÊÕÅ¤¾Ø×´Ì¬
          signal VCU_RegenTorqueValid_oVCU_chassis_oKAMA_FP_EPSChassis1_0303: start 12, 1 bit, big-endian, i-signal-type=PRIMITIVE, init-value=0, base-type=boolean, compu-method=CM_VCU_RegenTorqueValid, data-constr=DC_VCU_RegenTorqueValid, transfer-property=PENDING  # µç»ú×î´óÖÆ¶¯»ØÊÕÅ¤¾ØÓÐÐ§ÐÔ
          signal VCU_RegenTorqueCap_oVCU_chassis_oKAMA_FP_EPSChassis1_0303: start 23, 16 bit, big-endian, i-signal-type=PRIMITIVE, init-value=20000, base-type=uint16, compu-method=CM_VCU_RegenTorqueCap, data-constr=DC_VCU_RegenTorqueCap, unit=U_Nm, transfer-property=PENDING  # µç»ú×î´óÖÆ¶¯»ØÊÕÅ¤¾Ø
          signal VCU_WheelTrqACT_oVCU_chassis_oKAMA_FP_EPSChassis1_0303: start 39, 16 bit, big-endian, i-signal-type=PRIMITIVE, init-value=20000, base-type=uint16, compu-method=CM_VCU_WheelTrqACT, data-constr=DC_VCU_WheelTrqACT, unit=U_Nm, transfer-property=PENDING  # Êµ¼Êµç»úÅ¤¾Ø-ÂÖ¶Ë
          signal MessageCounter_152_oVCU_chassis_oKAMA_FP_EPSChassis1_0303: start 51, 4 bit, big-endian, i-signal-type=PRIMITIVE, init-value=0, base-type=uint8, compu-method=CM_MessageCounter_152, data-constr=DC_MessageCounter_152, transfer-property=PENDING  # AliveCounter_xxx
          signal Checksum_152_oVCU_chassis_oKAMA_FP_EPSChassis1_0303: start 63, 8 bit, big-endian, i-signal-type=PRIMITIVE, init-value=0, base-type=uint8, compu-method=CM_Checksum_152, data-constr=DC_Checksum_152, transfer-property=PENDING  # CRC-XXX
      frame VCU_HMIsignals_oKAMA_FP_EPSChassis1_0303: id 0x27B, from VCU, frame-length=8, can-addressing-mode=STANDARD
        pdu VCU_HMIsignals_oKAMA_FP_EPSChassis1_0303: length=8, minimum-delay=0, transmission-mode-false-timing=cyclic-timing={time-offset=0, time-period=0.2}, transmission-mode-true-timing=cyclic-timing={time-offset=0, time-period=0.2}, unused-bit-pattern=0
          signal VCU_HVILError_oVCU_HMIsignals_oKAMA_FP_EPSChassis1_0303: start 0, 1 bit, big-endian, i-signal-type=PRIMITIVE, init-value=0, base-type=boolean, compu-method=CM_VCU_HVILError, data-constr=DC_VCU_HVILError, transfer-property=PENDING  # HVIL error (Interlock monitoring device): required via GB/T 19836
          signal VCU_HVBatOvrTemp_oVCU_HMIsignals_oKAMA_FP_EPSChassis1_0303: start 1, 1 bit, big-endian, i-signal-type=PRIMITIVE, init-value=0, base-type=boolean, compu-method=CM_VCU_HVBatOvrTemp, data-constr=DC_VCU_HVBatOvrTemp, transfer-property=PENDING
          signal VCU_HVBatUndTemp_oVCU_HMIsignals_oKAMA_FP_EPSChassis1_0303: start 2, 1 bit, big-endian, i-signal-type=PRIMITIVE, init-value=0, base-type=boolean, compu-method=CM_VCU_HVBatUndTemp, data-constr=DC_VCU_HVBatUndTemp, transfer-property=PENDING
          signal VCU_DCDCFail_oVCU_HMIsignals_oKAMA_FP_EPSChassis1_0303: start 3, 1 bit, big-endian, i-signal-type=PRIMITIVE, init-value=0, base-type=boolean, compu-method=CM_VCU_DCDCFail, data-constr=DC_VCU_DCDCFail, transfer-property=PENDING
          signal VCU_HVBatCriFail_oVCU_HMIsignals_oKAMA_FP_EPSChassis1_0303: start 4, 1 bit, big-endian, i-signal-type=PRIMITIVE, init-value=0, base-type=boolean, compu-method=CM_VCU_HVBatCriFail, data-constr=DC_VCU_HVBatCriFail, transfer-property=PENDING  # Traction battery failure: GB/T 4094.2, Table 2, No. 1
          signal VCU_DriveMotOvrTemp_oVCU_HMIsignals_oKAMA_FP_EPSChassis1_0303: start 5, 1 bit, big-endian, i-signal-type=PRIMITIVE, init-value=0, base-type=boolean, compu-method=CM_VCU_DriveMotOvrTemp, data-constr=DC_VCU_DriveMotOvrTemp, transfer-property=PENDING  # Over-temp required via GB/T 19836. Additional components may be needed.
          signal VCU_DriveMotOverSpd_oVCU_HMIsignals_oKAMA_FP_EPSChassis1_0303: start 6, 1 bit, big-endian, i-signal-type=PRIMITIVE, init-value=0, base-type=boolean, compu-method=CM_VCU_DriveMotOverSpd, data-constr=DC_VCU_DriveMotOverSpd, transfer-property=PENDING  # Over-speeding: required via GB/T 19836
          signal VCU_CriSysFailure_oVCU_HMIsignals_oKAMA_FP_EPSChassis1_0303: start 7, 1 bit, big-endian, i-signal-type=PRIMITIVE, init-value=0, base-type=boolean, compu-method=CM_VCU_CriSysFailure, data-constr=DC_VCU_CriSysFailure, transfer-property=PENDING  # System failure tell-tale: GB/T 4094.2, Table 2, No. 3
          signal VCU_DegradedRegenBraking_oVCU_HMIsignals_oKAMA_FP_EPSChassis1_0303: start 8, 1 bit, big-endian, i-signal-type=PRIMITIVE, init-value=0, base-type=boolean, compu-method=CM_VCU_DegradedRegenBraking, data-constr=DC_VCU_DegradedRegenBraking, transfer-property=PENDING  # Regenerative Braking Perfromance Degradation Display Information
          signal VCU_DegradedPerformance_oVCU_HMIsignals_oKAMA_FP_EPSChassis1_0303: start 9, 1 bit, big-endian, i-signal-type=PRIMITIVE, init-value=0, base-type=boolean, compu-method=CM_VCU_DegradedPerformance, data-constr=DC_VCU_DegradedPerformance, transfer-property=PENDING  # Degraded Performance Display Information
          signal VCU_DrvDirCtrlFlt_oVCU_HMIsignals_oKAMA_FP_EPSChassis1_0303: start 10, 1 bit, big-endian, i-signal-type=PRIMITIVE, init-value=0, base-type=boolean, compu-method=CM_VCU_DrvDirCtrlFlt, data-constr=DC_VCU_DrvDirCtrlFlt, transfer-property=PENDING  # Drive Direction Control Fault Flag
          signal VCU_HVBatCoolOvrTemp_oVCU_HMIsignals_oKAMA_FP_EPSChassis1_0303: start 12, 1 bit, big-endian, i-signal-type=PRIMITIVE, init-value=0, base-type=boolean, compu-method=CM_VCU_HVBatCoolOvrTemp, data-constr=DC_VCU_HVBatCoolOvrTemp, transfer-property=PENDING  # Over-temp required via GB/T 19836. Additional components may be needed.
          signal VCU_LimpHome_oVCU_HMIsignals_oKAMA_FP_EPSChassis1_0303: start 13, 1 bit, big-endian, i-signal-type=PRIMITIVE, init-value=0, base-type=boolean, compu-method=CM_VCU_LimpHome, data-constr=DC_VCU_LimpHome, transfer-property=PENDING  # Limp home: GB/T 4094.2, Table 1, No. 3
          signal VCU_HVInsulResFault_oVCU_HMIsignals_oKAMA_FP_EPSChassis1_0303: start 14, 1 bit, big-endian, i-signal-type=PRIMITIVE, init-value=0, base-type=boolean, compu-method=CM_VCU_HVInsulResFault, data-constr=DC_VCU_HVInsulResFault, transfer-property=PENDING  # Insulation resistance/creepage distance indication: rrequired via GB/T 19836
          signal VCU_HVBatLowSocWar_oVCU_HMIsignals_oKAMA_FP_EPSChassis1_0303: start 15, 1 bit, big-endian, i-signal-type=PRIMITIVE, init-value=0, base-type=boolean, compu-method=CM_VCU_HVBatLowSocWar, data-constr=DC_VCU_HVBatLowSocWar, transfer-property=PENDING  # HV Battery low SoC: GB/T 4094.2, Table 1, No. 1
          signal VCU_UnavailRegenBraking_oVCU_HMIsignals_oKAMA_FP_EPSChassis1_0303: start 23, 1 bit, big-endian, i-signal-type=PRIMITIVE, init-value=0, base-type=boolean, compu-method=CM_VCU_UnavailRegenBraking, data-constr=DC_VCU_UnavailRegenBraking, transfer-property=PENDING  # Regeneration Unavailable Display Information
          signal VCU_FrMotorSpd_oVCU_HMIsignals_oKAMA_FP_EPSChassis1_0303: start 31, 8 bit, big-endian, i-signal-type=PRIMITIVE, init-value=0, base-type=uint8, compu-method=CM_VCU_FrMotorSpd, data-constr=DC_VCU_FrMotorSpd, unit=U_rpm, transfer-property=PENDING  # Front Drive Motor Speed for Display
          signal VCU_RrMotorSpd_oVCU_HMIsignals_oKAMA_FP_EPSChassis1_0303: start 39, 8 bit, big-endian, i-signal-type=PRIMITIVE, init-value=0, base-type=uint8, compu-method=CM_VCU_RrMotorSpd, data-constr=DC_VCU_RrMotorSpd, unit=U_rpm, transfer-property=PENDING  # Rear Drive Motor Speed for Display
          signal VCU_InvldGearSel_oVCU_HMIsignals_oKAMA_FP_EPSChassis1_0303: start 47, 4 bit, big-endian, i-signal-type=PRIMITIVE, init-value=0, base-type=uint8, compu-method=CM_VCU_InvldGearSel, data-constr=DC_VCU_InvldGearSel, transfer-property=PENDING  # Invalid Gear Selection Flag
          signal MessageCounter_27B_oVCU_HMIsignals_oKAMA_FP_EPSChassis1_0303: start 51, 4 bit, big-endian, i-signal-type=PRIMITIVE, init-value=0, base-type=uint8, compu-method=CM_MessageCounter_27B, data-constr=DC_MessageCounter_27B, transfer-property=PENDING  # AliveCounter_xxx
          signal Checksum_27B_oVCU_HMIsignals_oKAMA_FP_EPSChassis1_0303: start 63, 8 bit, big-endian, i-signal-type=PRIMITIVE, init-value=0, base-type=uint8, compu-method=CM_Checksum_27B, data-constr=DC_Checksum_27B, transfer-property=PENDING  # CRC-XXX
      frame VCU_HVbattStatus1_oKAMA_FP_EPSChassis1_0303: id 0x27C, from VCU, frame-length=8, can-addressing-mode=STANDARD
        pdu VCU_HVbattStatus1_oKAMA_FP_EPSChassis1_0303: length=8, minimum-delay=0, transmission-mode-false-timing=cyclic-timing={time-offset=0, time-period=0.2}, transmission-mode-true-timing=cyclic-timing={time-offset=0, time-period=0.2}, unused-bit-pattern=0
          signal VCU_AvaDrvRange_oVCU_HVbattStatus1_oKAMA_FP_EPSChassis1_0303: start 7, 10 bit, big-endian, i-signal-type=PRIMITIVE, init-value=0, base-type=uint16, compu-method=CM_VCU_AvaDrvRange, data-constr=DC_VCU_AvaDrvRange, unit=U_km, transfer-property=PENDING  # Available driving range to the user.
          signal VCU_EnergyReturnedRegen_oVCU_HVbattStatus1_oKAMA_FP_EPSChassis1_0303: start 9, 10 bit, big-endian, i-signal-type=PRIMITIVE, init-value=0, base-type=uint16, compu-method=CM_VCU_EnergyReturnedRegen, data-constr=DC_VCU_EnergyReturnedRegen, unit=U_kWh, transfer-property=PENDING  # Total electrical energy recovered by regeneration in the current drive cycle.
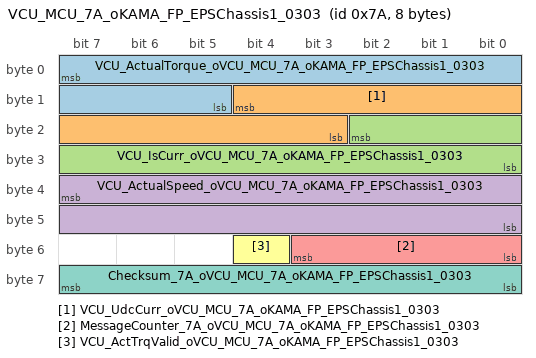
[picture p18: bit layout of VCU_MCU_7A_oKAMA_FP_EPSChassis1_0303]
      frame VCU_MCU_7A_oKAMA_FP_EPSChassis1_0303: id 0x7A, from VCU, frame-length=8, can-addressing-mode=STANDARD
        pdu VCU_MCU_7A_oKAMA_FP_EPSChassis1_0303: length=8, minimum-delay=0, transmission-mode-false-timing=cyclic-timing={time-offset=0, time-period=0.01}, transmission-mode-true-timing=cyclic-timing={time-offset=0, time-period=0.01}, unused-bit-pattern=0
          signal VCU_ActualTorque_oVCU_MCU_7A_oKAMA_FP_EPSChassis1_0303: start 7, 11 bit, big-endian, i-signal-type=PRIMITIVE, init-value=1024, base-type=uint16, compu-method=CM_VCU_ActualTorque, data-constr=DC_VCU_ActualTorque, transfer-property=PENDING  # the actual torque of motorµç»úÊµÊ±Á¦¾Ø
          signal VCU_UdcCurr_oVCU_MCU_7A_oKAMA_FP_EPSChassis1_0303: start 12, 10 bit, big-endian, i-signal-type=PRIMITIVE, init-value=0, base-type=uint16, compu-method=CM_VCU_UdcCurr, data-constr=DC_VCU_UdcCurr, transfer-property=PENDING  # the actual voltage of udclinkÊµÊ±Ö±Á÷µçÑ¹
          signal VCU_IsCurr_oVCU_MCU_7A_oKAMA_FP_EPSChassis1_0303: start 18, 11 bit, big-endian, i-signal-type=PRIMITIVE, init-value=0, base-type=uint16, compu-method=CM_VCU_IsCurr, data-constr=DC_VCU_IsCurr, transfer-property=PENDING  # the actual current ÊµÊ±Ö±Á÷µçÁ÷£¨¹ÀËãµçÁ÷£©
          signal VCU_ActualSpeed_oVCU_MCU_7A_oKAMA_FP_EPSChassis1_0303: start 39, 16 bit, big-endian, i-signal-type=PRIMITIVE, init-value=32768, base-type=uint16, compu-method=CM_VCU_ActualSpeed, data-constr=DC_VCU_ActualSpeed, transfer-property=PENDING  # the actual motor speedµç»úÊµÊ±×ªËÙ
          signal MessageCounter_7A_oVCU_MCU_7A_oKAMA_FP_EPSChassis1_0303: start 51, 4 bit, big-endian, i-signal-type=PRIMITIVE, init-value=0, base-type=uint8, compu-method=CM_MessageCounter_7A, data-constr=DC_MessageCounter_7A, transfer-property=PENDING  # rolling counter
          signal VCU_ActTrqValid_oVCU_MCU_7A_oKAMA_FP_EPSChassis1_0303: start 52, 1 bit, big-endian, i-signal-type=PRIMITIVE, init-value=0, base-type=boolean, compu-method=CM_VCU_ActTrqValid, data-constr=DC_VCU_ActTrqValid, transfer-property=PENDING  # Actual torque valid
          signal Checksum_7A_oVCU_MCU_7A_oKAMA_FP_EPSChassis1_0303: start 63, 8 bit, big-endian, i-signal-type=PRIMITIVE, init-value=0, base-type=uint8, compu-method=CM_Checksum_7A, data-constr=DC_Checksum_7A, transfer-property=PENDING  # checksum
      frame VCU_OdometerInfo_oKAMA_FP_EPSChassis1_0303: id 0x279, from VCU, frame-length=3, can-addressing-mode=STANDARD
        pdu VCU_OdometerInfo_oKAMA_FP_EPSChassis1_0303: length=3, minimum-delay=0, transmission-mode-false-timing=cyclic-timing={time-offset=0, time-period=2}, transmission-mode-true-timing=cyclic-timing={time-offset=0, time-period=2}, unused-bit-pattern=0
          signal VCU_OdometerInfo_VCU_oVCU_OdometerInfo_oKAMA_FP_EPSChassis1_0303: start 7, 20 bit, big-endian, i-signal-type=PRIMITIVE, init-value=0, base-type=uint32, compu-method=CM_VCU_OdometerInfo_VCU, data-constr=DC_VCU_OdometerInfo_VCU, unit=U_km, transfer-property=PENDING  # odometer
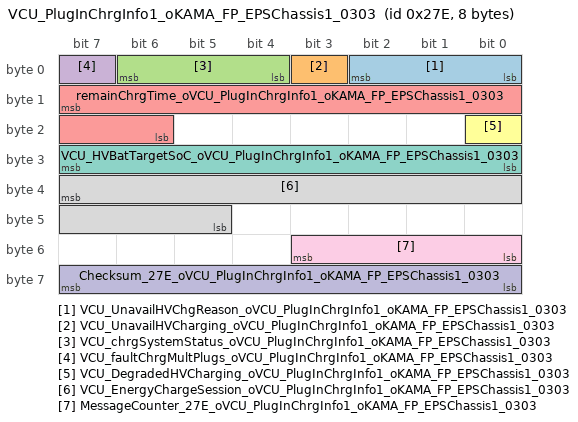
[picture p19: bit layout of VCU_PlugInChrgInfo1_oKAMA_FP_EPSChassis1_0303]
      frame VCU_PlugInChrgInfo1_oKAMA_FP_EPSChassis1_0303: id 0x27E, from VCU, frame-length=8, can-addressing-mode=STANDARD
        pdu VCU_PlugInChrgInfo1_oKAMA_FP_EPSChassis1_0303: length=8, minimum-delay=0, transmission-mode-false-timing=cyclic-timing={time-offset=0, time-period=0.5}, transmission-mode-true-timing=cyclic-timing={time-offset=0, time-period=0.5}, unused-bit-pattern=0
          signal VCU_UnavailHVChgReason_oVCU_PlugInChrgInfo1_oKAMA_FP_EPSChassis1_0303: start 2, 3 bit, big-endian, i-signal-type=PRIMITIVE, init-value=0, base-type=uint8, compu-method=CM_VCU_UnavailHVChgReason, data-constr=DC_VCU_UnavailHVChgReason, transfer-property=PENDING  # HV Battery Charging Fault Reason
          signal VCU_UnavailHVCharging_oVCU_PlugInChrgInfo1_oKAMA_FP_EPSChassis1_0303: start 3, 1 bit, big-endian, i-signal-type=PRIMITIVE, init-value=0, base-type=boolean, compu-method=CM_VCU_UnavailHVCharging, data-constr=DC_VCU_UnavailHVCharging, transfer-property=PENDING  # Charging Availability Flag
          signal VCU_chrgSystemStatus_oVCU_PlugInChrgInfo1_oKAMA_FP_EPSChassis1_0303: start 6, 3 bit, big-endian, i-signal-type=PRIMITIVE, init-value=0, base-type=uint8, compu-method=CM_VCU_chrgSystemStatus, data-constr=DC_VCU_chrgSystemStatus, transfer-property=PENDING
          signal VCU_faultChrgMultPlugs_oVCU_PlugInChrgInfo1_oKAMA_FP_EPSChassis1_0303: start 7, 1 bit, big-endian, i-signal-type=PRIMITIVE, init-value=0, base-type=boolean, compu-method=CM_VCU_faultChrgMultPlugs, data-constr=DC_VCU_faultChrgMultPlugs, transfer-property=PENDING
          signal remainChrgTime_oVCU_PlugInChrgInfo1_oKAMA_FP_EPSChassis1_0303: start 15, 10 bit, big-endian, i-signal-type=PRIMITIVE, init-value=0, base-type=uint16, compu-method=CM_remainChrgTime, data-constr=DC_remainChrgTime, transfer-property=PENDING
          signal VCU_DegradedHVCharging_oVCU_PlugInChrgInfo1_oKAMA_FP_EPSChassis1_0303: start 16, 1 bit, big-endian, i-signal-type=PRIMITIVE, init-value=0, base-type=boolean, compu-method=CM_VCU_DegradedHVCharging, data-constr=DC_VCU_DegradedHVCharging, transfer-property=PENDING  # Charging Performance Flag
          signal VCU_HVBatTargetSoC_oVCU_PlugInChrgInfo1_oKAMA_FP_EPSChassis1_0303: start 31, 8 bit, big-endian, i-signal-type=PRIMITIVE, init-value=0, base-type=uint8, compu-method=CM_VCU_HVBatTargetSoC, data-constr=DC_VCU_HVBatTargetSoC, unit=U_p, transfer-property=PENDING  # HV Battery Target SoC Feedback from Customer Setting
          signal VCU_EnergyChargeSession_oVCU_PlugInChrgInfo1_oKAMA_FP_EPSChassis1_0303: start 39, 11 bit, big-endian, i-signal-type=PRIMITIVE, init-value=0, base-type=uint16, compu-method=CM_VCU_EnergyChargeSession, data-constr=DC_VCU_EnergyChargeSession, unit=U_kWh, transfer-property=PENDING  # Total electrical energy accumulated in the current charge session
          signal MessageCounter_27E_oVCU_PlugInChrgInfo1_oKAMA_FP_EPSChassis1_0303: start 51, 4 bit, big-endian, i-signal-type=PRIMITIVE, init-value=0, base-type=uint8, compu-method=CM_MessageCounter_27E, data-constr=DC_MessageCounter_27E, transfer-property=PENDING  # AliveCounter_xxx
          signal Checksum_27E_oVCU_PlugInChrgInfo1_oKAMA_FP_EPSChassis1_0303: start 63, 8 bit, big-endian, i-signal-type=PRIMITIVE, init-value=0, base-type=uint8, compu-method=CM_Checksum_27E, data-constr=DC_Checksum_27E, transfer-property=PENDING  # CRC-XXX
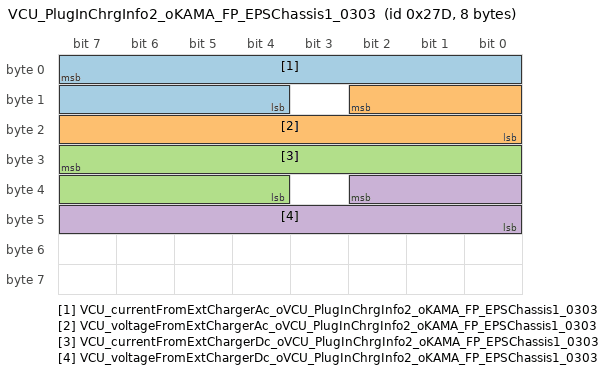
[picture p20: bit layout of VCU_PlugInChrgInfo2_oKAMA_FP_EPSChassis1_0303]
      frame VCU_PlugInChrgInfo2_oKAMA_FP_EPSChassis1_0303: id 0x27D, from VCU, frame-length=8, can-addressing-mode=STANDARD
        pdu VCU_PlugInChrgInfo2_oKAMA_FP_EPSChassis1_0303: length=8, minimum-delay=0, transmission-mode-false-timing=cyclic-timing={time-offset=0, time-period=0.2}, transmission-mode-true-timing=cyclic-timing={time-offset=0, time-period=0.2}, unused-bit-pattern=0
          signal VCU_currentFromExtChargerAc_oVCU_PlugInChrgInfo2_oKAMA_FP_EPSChassis1_0303: start 7, 12 bit, big-endian, i-signal-type=PRIMITIVE, init-value=0, base-type=uint16, compu-method=CM_VCU_currentFromExtChargerAc, data-constr=DC_VCU_currentFromExtChargerAc, unit=U_A, transfer-property=PENDING
          signal VCU_voltageFromExtChargerAc_oVCU_PlugInChrgInfo2_oKAMA_FP_EPSChassis1_0303: start 10, 11 bit, big-endian, i-signal-type=PRIMITIVE, init-value=0, base-type=uint16, compu-method=CM_VCU_voltageFromExtChargerAc, data-constr=DC_VCU_voltageFromExtChargerAc, unit=U_V, transfer-property=PENDING
          signal VCU_currentFromExtChargerDc_oVCU_PlugInChrgInfo2_oKAMA_FP_EPSChassis1_0303: start 31, 12 bit, big-endian, i-signal-type=PRIMITIVE, init-value=0, base-type=uint16, compu-method=CM_VCU_currentFromExtChargerDc, data-constr=DC_VCU_currentFromExtChargerDc, unit=U_A, transfer-property=PENDING
          signal VCU_voltageFromExtChargerDc_oVCU_PlugInChrgInfo2_oKAMA_FP_EPSChassis1_0303: start 34, 11 bit, big-endian, i-signal-type=PRIMITIVE, init-value=0, base-type=uint16, compu-method=CM_VCU_voltageFromExtChargerDc, data-constr=DC_VCU_voltageFromExtChargerDc, unit=U_V, transfer-property=PENDING
      frame VCU_PwrtrainHVbattStatus2_oKAMA_FP_EPSChassis1_0303: id 0x27F, from VCU, frame-length=8, can-addressing-mode=STANDARD
        pdu VCU_PwrtrainHVbattStatus2_oKAMA_FP_EPSChassis1_0303: length=8, minimum-delay=0, transmission-mode-false-timing=cyclic-timing={time-offset=0, time-period=0.2}, transmission-mode-true-timing=cyclic-timing={time-offset=0, time-period=0.2}, unused-bit-pattern=0
          signal VCU_HVBatCurrent_VCU_oVCU_PwrtrainHVbattStatus2_oKAMA_FP_EPSChassis1_0303: start 15, 14 bit, big-endian, i-signal-type=PRIMITIVE, init-value=8190, base-type=uint16, compu-method=CM_VCU_HVBatCurrent_VCU, data-constr=DC_VCU_HVBatCurrent_VCU, unit=U_A, transfer-property=PENDING  # HV Battery current: required via GB/T 19836
          signal VCU_HVBatVolt_VCU_oVCU_PwrtrainHVbattStatus2_oKAMA_FP_EPSChassis1_0303: start 31, 12 bit, big-endian, i-signal-type=PRIMITIVE, init-value=0, base-type=uint16, compu-method=CM_VCU_HVBatVolt_VCU, data-constr=DC_VCU_HVBatVolt_VCU, unit=U_V, transfer-property=PENDING  # HV Battery voltage: required via GB/T 19836
          signal MessageCounter_27F_oVCU_PwrtrainHVbattStatus2_oKAMA_FP_EPSChassis1_0303: start 51, 4 bit, big-endian, i-signal-type=PRIMITIVE, init-value=0, base-type=uint8, compu-method=CM_MessageCounter_27F, data-constr=DC_MessageCounter_27F, transfer-property=PENDING  # AliveCounter_xxx
          signal Checksum_27F_oVCU_PwrtrainHVbattStatus2_oKAMA_FP_EPSChassis1_0303: start 63, 8 bit, big-endian, i-signal-type=PRIMITIVE, init-value=0, base-type=uint8, compu-method=CM_Checksum_27F, data-constr=DC_Checksum_27F, transfer-property=PENDING  # CRC-XXX
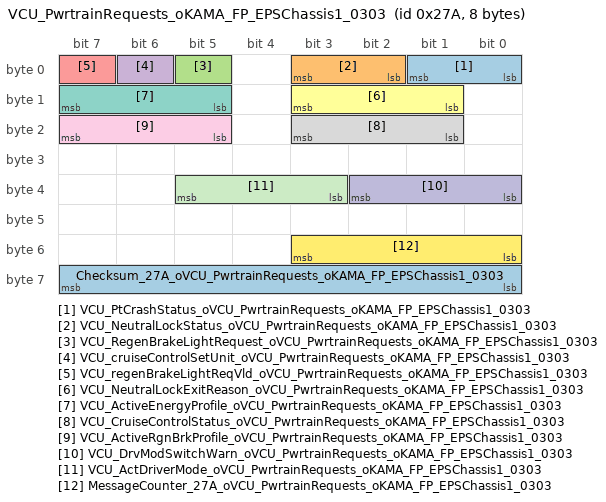
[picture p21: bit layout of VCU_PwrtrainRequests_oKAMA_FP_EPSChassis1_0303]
      frame VCU_PwrtrainRequests_oKAMA_FP_EPSChassis1_0303: id 0x27A, from VCU, frame-length=8, can-addressing-mode=STANDARD
        pdu VCU_PwrtrainRequests_oKAMA_FP_EPSChassis1_0303: length=8, minimum-delay=0, transmission-mode-false-timing=cyclic-timing={time-offset=0, time-period=0.1}, transmission-mode-true-timing=cyclic-timing={time-offset=0, time-period=0.1}, unused-bit-pattern=0
          signal VCU_PtCrashStatus_oVCU_PwrtrainRequests_oKAMA_FP_EPSChassis1_0303: start 1, 2 bit, big-endian, i-signal-type=PRIMITIVE, init-value=0, base-type=uint8, compu-method=CM_VCU_PtCrashStatus, data-constr=DC_VCU_PtCrashStatus, transfer-property=PENDING  # Powertrain Crash Detection Signal Status
          signal VCU_NeutralLockStatus_oVCU_PwrtrainRequests_oKAMA_FP_EPSChassis1_0303: start 3, 2 bit, big-endian, i-signal-type=PRIMITIVE, init-value=0, base-type=uint8, compu-method=CM_VCU_NeutralLockStatus, data-constr=DC_VCU_NeutralLockStatus, transfer-property=PENDING  # Neutral Lock Status
          signal VCU_RegenBrakeLightRequest_oVCU_PwrtrainRequests_oKAMA_FP_EPSChassis1_0303: start 5, 1 bit, big-endian, i-signal-type=PRIMITIVE, init-value=0, base-type=boolean, compu-method=CM_VCU_RegenBrakeLightRequest, data-constr=DC_VCU_RegenBrakeLightRequest, transfer-property=PENDING  # Request to illuminate the brake lights from the Powertrain if regen creates deceleration greater than 0.07g.
          signal VCU_cruiseControlSetUnit_oVCU_PwrtrainRequests_oKAMA_FP_EPSChassis1_0303: start 6, 1 bit, big-endian, i-signal-type=PRIMITIVE, init-value=0, base-type=boolean, compu-method=CM_VCU_cruiseControlSetUnit, data-constr=DC_VCU_cruiseControlSetUnit, transfer-property=PENDING  # Cruise Control Set Unit for Display
          signal VCU_regenBrakeLightReqVld_oVCU_PwrtrainRequests_oKAMA_FP_EPSChassis1_0303: start 7, 1 bit, big-endian, i-signal-type=PRIMITIVE, init-value=0, base-type=boolean, compu-method=CM_VCU_regenBrakeLightReqVld, data-constr=DC_VCU_regenBrakeLightReqVld, transfer-property=PENDING
          signal VCU_NeutralLockExitReason_oVCU_PwrtrainRequests_oKAMA_FP_EPSChassis1_0303: start 11, 3 bit, big-endian, i-signal-type=PRIMITIVE, init-value=0, base-type=uint8, compu-method=CM_VCU_NeutralLockExitReason, data-constr=DC_VCU_NeutralLockExitReason, transfer-property=PENDING  # Neutral Lock Exit Reason
          signal VCU_ActiveEnergyProfile_oVCU_PwrtrainRequests_oKAMA_FP_EPSChassis1_0303: start 15, 3 bit, big-endian, i-signal-type=PRIMITIVE, init-value=0, base-type=uint8, compu-method=CM_VCU_ActiveEnergyProfile, data-constr=DC_VCU_ActiveEnergyProfile, transfer-property=PENDING  # Active Energy Profile
          signal VCU_CruiseControlStatus_oVCU_PwrtrainRequests_oKAMA_FP_EPSChassis1_0303: start 19, 3 bit, big-endian, i-signal-type=PRIMITIVE, init-value=0, base-type=uint8, compu-method=CM_VCU_CruiseControlStatus, data-constr=DC_VCU_CruiseControlStatus, transfer-property=PENDING  # Cruise Control Status
          signal VCU_ActiveRgnBrkProfile_oVCU_PwrtrainRequests_oKAMA_FP_EPSChassis1_0303: start 23, 3 bit, big-endian, i-signal-type=PRIMITIVE, init-value=0, base-type=uint8, compu-method=CM_VCU_ActiveRgnBrkProfile, data-constr=DC_VCU_ActiveRgnBrkProfile, transfer-property=PENDING  # Active Regenerative Braking Profile
          signal VCU_DrvModSwitchWarn_oVCU_PwrtrainRequests_oKAMA_FP_EPSChassis1_0303: start 34, 3 bit, big-endian, i-signal-type=PRIMITIVE, init-value=0, base-type=uint8, compu-method=CM_VCU_DrvModSwitchWarn, data-constr=DC_VCU_DrvModSwitchWarn, transfer-property=PENDING  # ¼ÝÊ»Ä£Ê½ÇÐ»»Òì³£ÌáÊ¾
          signal VCU_ActDriverMode_oVCU_PwrtrainRequests_oKAMA_FP_EPSChassis1_0303: start 37, 3 bit, big-endian, i-signal-type=PRIMITIVE, init-value=0, base-type=uint8, compu-method=CM_VCU_ActDriverMode, data-constr=DC_VCU_ActDriverMode, transfer-property=PENDING  # Êµ¼Ê¼ÝÊ»Ä£Ê½
          signal MessageCounter_27A_oVCU_PwrtrainRequests_oKAMA_FP_EPSChassis1_0303: start 51, 4 bit, big-endian, i-signal-type=PRIMITIVE, init-value=0, base-type=uint8, compu-method=CM_MessageCounter_27A, data-constr=DC_MessageCounter_27A, transfer-property=PENDING  # AliveCounter_xxx
          signal Checksum_27A_oVCU_PwrtrainRequests_oKAMA_FP_EPSChassis1_0303: start 63, 8 bit, big-endian, i-signal-type=PRIMITIVE, init-value=0, base-type=uint8, compu-method=CM_Checksum_27A, data-constr=DC_Checksum_27A, transfer-property=PENDING  # CRC-XXX
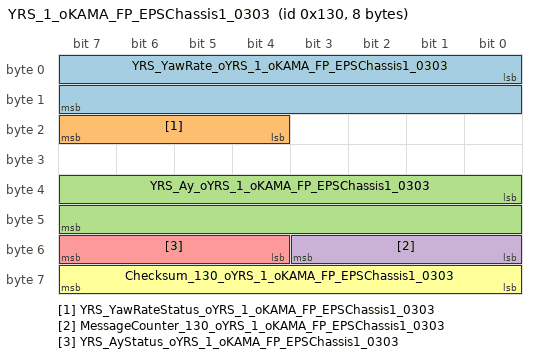
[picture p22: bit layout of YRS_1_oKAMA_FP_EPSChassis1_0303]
      frame YRS_1_oKAMA_FP_EPSChassis1_0303: id 0x130, to VCU, frame-length=8, can-addressing-mode=STANDARD
        pdu YRS_1_oKAMA_FP_EPSChassis1_0303: length=8, minimum-delay=0, transmission-mode-false-timing=cyclic-timing={time-offset=0, time-period=0.02}, transmission-mode-true-timing=cyclic-timing={time-offset=0, time-period=0.02}, unused-bit-pattern=0
          signal YRS_YawRate_oYRS_1_oKAMA_FP_EPSChassis1_0303: start 0, 16 bit, little-endian, i-signal-type=PRIMITIVE, init-value=32768, base-type=uint16, compu-method=CM_YRS_YawRate, data-constr=DC_YRS_YawRate, unit=U_Ys, transfer-property=PENDING, to VCU  # ºá°Ú½ÇËÙ¶ÈÐÅºÅ
          signal YRS_YawRateStatus_oYRS_1_oKAMA_FP_EPSChassis1_0303: start 20, 4 bit, little-endian, i-signal-type=PRIMITIVE, init-value=0, base-type=uint8, compu-method=CM_YRS_YawRateStatus, data-constr=DC_YRS_YawRateStatus, transfer-property=PENDING, to VCU  # ºá°Ú½ÇËÙ¶È×´Ì¬ÐÅºÅ
          signal YRS_Ay_oYRS_1_oKAMA_FP_EPSChassis1_0303: start 32, 16 bit, little-endian, i-signal-type=PRIMITIVE, init-value=32784.9293563579, base-type=uint16, compu-method=CM_YRS_Ay, data-constr=DC_YRS_Ay, unit=U_gYdigit, transfer-property=PENDING, to VCU  # ²àÏò¼ÓËÙ¶ÈÐÅºÅ
          signal MessageCounter_130_oYRS_1_oKAMA_FP_EPSChassis1_0303: start 48, 4 bit, little-endian, i-signal-type=PRIMITIVE, init-value=0, base-type=uint8, compu-method=CM_MessageCounter_130, data-constr=DC_MessageCounter_130, transfer-property=PENDING, to VCU  # YRS1±¨ÎÄÉúÃüÐÅºÅ
          signal YRS_AyStatus_oYRS_1_oKAMA_FP_EPSChassis1_0303: start 52, 4 bit, little-endian, i-signal-type=PRIMITIVE, init-value=0, base-type=uint8, compu-method=CM_YRS_AyStatus, data-constr=DC_YRS_AyStatus, transfer-property=PENDING, to VCU  # ²àÏò¼ÓËÙ¶È×´Ì¬ÐÅºÅ
          signal Checksum_130_oYRS_1_oKAMA_FP_EPSChassis1_0303: start 56, 8 bit, little-endian, i-signal-type=PRIMITIVE, init-value=0, base-type=uint8, compu-method=CM_Checksum_130, data-constr=DC_Checksum_130, transfer-property=PENDING, to VCU  # CRC J1850Ëã·¨Ð£ÑéËã·¨
      frame YRS_2_oKAMA_FP_EPSChassis1_0303: id 0x131, to VCU, frame-length=8, can-addressing-mode=STANDARD
        pdu YRS_2_oKAMA_FP_EPSChassis1_0303: length=8, minimum-delay=0, transmission-mode-false-timing=cyclic-timing={time-offset=0, time-period=0.02}, transmission-mode-true-timing=cyclic-timing={time-offset=0, time-period=0.02}, unused-bit-pattern=0
          signal YRS_Ax_oYRS_2_oKAMA_FP_EPSChassis1_0303: start 32, 16 bit, little-endian, i-signal-type=PRIMITIVE, init-value=32784.9293563579, base-type=uint16, compu-method=CM_YRS_Ax, data-constr=DC_YRS_Ax, unit=U_gYdigit, transfer-property=PENDING, to VCU  # ×ÝÏò¼ÓËÙ¶ÈÐÅºÅ
          signal MessageCounter_131_oYRS_2_oKAMA_FP_EPSChassis1_0303: start 48, 4 bit, little-endian, i-signal-type=PRIMITIVE, init-value=0, base-type=uint8, compu-method=CM_MessageCounter_131, data-constr=DC_MessageCounter_131, transfer-property=PENDING, to VCU  # YRS2±¨ÎÄÉúÃüÐÅºÅ
          signal YRS_AxStatus_oYRS_2_oKAMA_FP_EPSChassis1_0303: start 52, 4 bit, little-endian, i-signal-type=PRIMITIVE, init-value=0, base-type=uint8, compu-method=CM_YRS_AxStatus, data-constr=DC_YRS_AxStatus, transfer-property=PENDING, to VCU  # ×ÝÏò¼ÓËÙ¶È×´Ì¬ÐÅºÅ
          signal Checksum_131_oYRS_2_oKAMA_FP_EPSChassis1_0303: start 56, 8 bit, little-endian, i-signal-type=PRIMITIVE, init-value=0, base-type=uint8, compu-method=CM_Checksum_131, data-constr=DC_Checksum_131, transfer-property=PENDING, to VCU  # CRC J1850Ëã·¨Ð£ÑéËã·¨
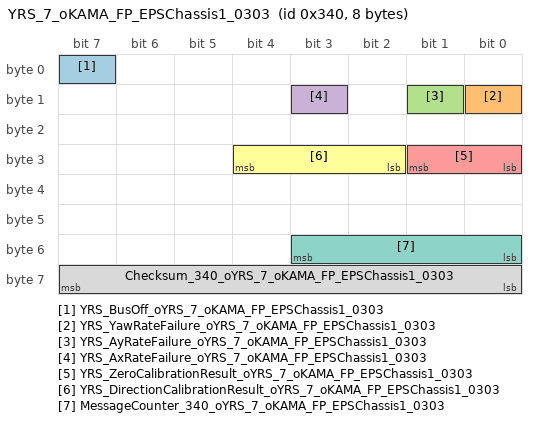
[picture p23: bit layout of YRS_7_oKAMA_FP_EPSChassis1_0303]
      frame YRS_7_oKAMA_FP_EPSChassis1_0303: id 0x340, to VCU, frame-length=8, can-addressing-mode=STANDARD
        pdu YRS_7_oKAMA_FP_EPSChassis1_0303: length=8, minimum-delay=0, transmission-mode-false-timing=cyclic-timing={time-offset=0, time-period=0.1}, transmission-mode-true-timing=cyclic-timing={time-offset=0, time-period=0.1}, unused-bit-pattern=0
          signal YRS_BusOff_oYRS_7_oKAMA_FP_EPSChassis1_0303: start 7, 1 bit, little-endian, i-signal-type=PRIMITIVE, init-value=0, base-type=boolean, compu-method=CM_YRS_BusOff, data-constr=DC_YRS_BusOff, transfer-property=PENDING, to VCU  # Bus Off±êÖ¾Î»
          signal YRS_YawRateFailure_oYRS_7_oKAMA_FP_EPSChassis1_0303: start 8, 1 bit, little-endian, i-signal-type=PRIMITIVE, init-value=0, base-type=boolean, compu-method=CM_YRS_YawRateFailure, data-constr=DC_YRS_YawRateFailure, transfer-property=PENDING, to VCU  # ºá°Ú½ÇËÙ¶È´íÎó±êÖ¾Î»
          signal YRS_AyRateFailure_oYRS_7_oKAMA_FP_EPSChassis1_0303: start 9, 1 bit, little-endian, i-signal-type=PRIMITIVE, init-value=0, base-type=boolean, compu-method=CM_YRS_AyRateFailure, data-constr=DC_YRS_AyRateFailure, transfer-property=PENDING, to VCU  # ²àÏò¼ÓËÙ¶È´íÎó±êÖ¾Î»
          signal YRS_AxRateFailure_oYRS_7_oKAMA_FP_EPSChassis1_0303: start 11, 1 bit, little-endian, i-signal-type=PRIMITIVE, init-value=0, base-type=boolean, compu-method=CM_YRS_AxRateFailure, data-constr=DC_YRS_AxRateFailure, transfer-property=PENDING, to VCU  # ×ÝÏò¼ÓËÙ¶È´íÎó±êÖ¾Î»
          signal YRS_ZeroCalibrationResult_oYRS_7_oKAMA_FP_EPSChassis1_0303: start 24, 2 bit, little-endian, i-signal-type=PRIMITIVE, init-value=0, base-type=uint8, compu-method=CM_YRS_ZeroCalibrationResult, data-constr=DC_YRS_ZeroCalibrationResult, transfer-property=PENDING, to VCU  # Áãµã±ê¶¨½á¹û±êÖ¾Î»
          signal YRS_DirectionCalibrationResult_oYRS_7_oKAMA_FP_EPSChassis1_0303: start 26, 3 bit, little-endian, i-signal-type=PRIMITIVE, init-value=0, base-type=uint8, compu-method=CM_YRS_DirectionCalibrationResult, data-constr=DC_YRS_DirectionCalibrationResult, transfer-property=PENDING, to VCU  # ·½Ïò±ê¶¨½á¹û±êÖ¾Î»
          signal MessageCounter_340_oYRS_7_oKAMA_FP_EPSChassis1_0303: start 48, 4 bit, little-endian, i-signal-type=PRIMITIVE, init-value=0, base-type=uint8, compu-method=CM_MessageCounter_340, data-constr=DC_MessageCounter_340, transfer-property=PENDING, to VCU  # YRS7±¨ÎÄÉúÃüÐÅºÅ
          signal Checksum_340_oYRS_7_oKAMA_FP_EPSChassis1_0303: start 56, 8 bit, little-endian, i-signal-type=PRIMITIVE, init-value=0, base-type=uint8, compu-method=CM_Checksum_340, data-constr=DC_Checksum_340, transfer-property=PENDING, to VCU  # CRC J1850Ëã·¨Ð£ÑéËã·¨
